AUTOSAR XML (schema 00050)
package /FCADT/ComponentTypes
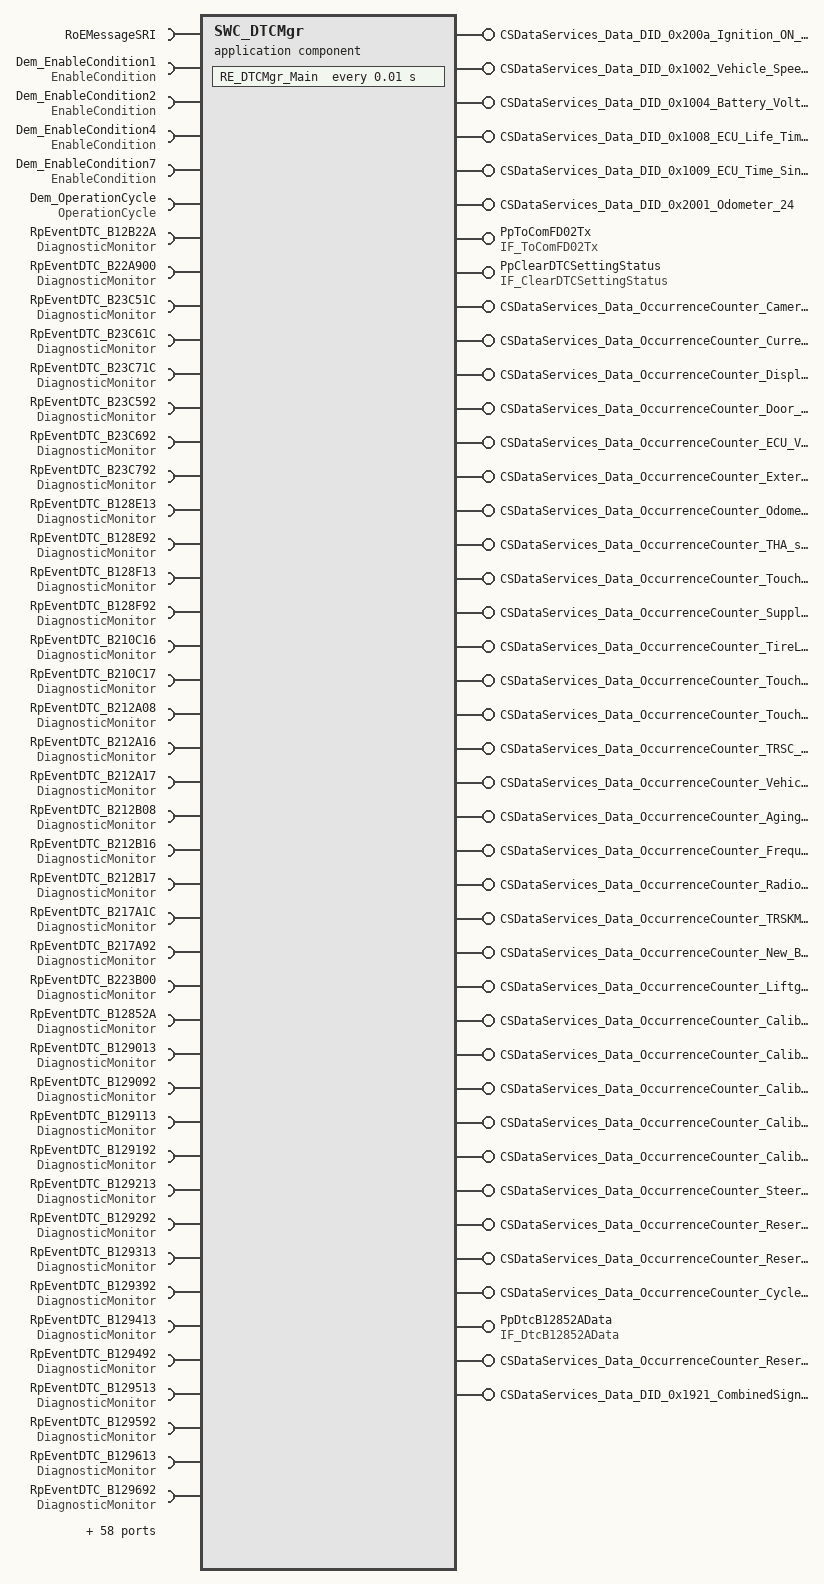
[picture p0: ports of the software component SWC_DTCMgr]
  application sw component type SWC_DTCMgr
    require port RoEMessageSRI: nonqueued-receiver-com-spec{data-element=Data, init-value=8 x 0}, required-interface=RoEMessageSRI
    6 x provide port, all with server-com-spec{operation=ReadData, queue-length=1}:
      CSDataServices_Data_DID_0x200a_Ignition_ON_Counter_24: provided-interface=CSDataServices_Data_DID_0x200a_Ignition_ON_Counter_24
      CSDataServices_Data_DID_0x1002_Vehicle_Speed_24: provided-interface=CSDataServices_Data_DID_0x1002_Vehicle_Speed_24
      CSDataServices_Data_DID_0x1004_Battery_Voltage_24: provided-interface=CSDataServices_Data_DID_0x1004_Battery_Voltage_24
      CSDataServices_Data_DID_0x1008_ECU_Life_Time_24: provided-interface=CSDataServices_Data_DID_0x1008_ECU_Life_Time_24
      CSDataServices_Data_DID_0x1009_ECU_Time_Since_Ignition_ON: provided-interface=CSDataServices_Data_DID_0x1009_ECU_Time_Since_Ignition_ON
      CSDataServices_Data_DID_0x2001_Odometer_24: provided-interface=CSDataServices_Data_DID_0x2001_Odometer_24
    84 x require port:
      Dem_EnableCondition1: client-com-spec=SetEnableCondition, required-interface=EnableCondition
      Dem_EnableCondition2: client-com-spec=SetEnableCondition, required-interface=EnableCondition
      Dem_EnableCondition4: client-com-spec=SetEnableCondition, required-interface=EnableCondition
      Dem_EnableCondition7: client-com-spec=SetEnableCondition, required-interface=EnableCondition
      Dem_OperationCycle: required-com-specs=[SetOperationCycleState, GetOperationCycleState], required-interface=OperationCycle
      RpEventDTC_B12B22A: required-interface=DiagnosticMonitor
        required-com-specs:
          SetEventStatus
          GetEventExtendedDataRecordEx
          GetEventFreezeFrameDataEx
          GetFaultDetectionCounter
          GetDTCOfEvent
          GetEventTested
          GetEventFailed
          GetEventStatus
          GetEventUdsStatus
          ResetEventDebounceStatus
          ResetEventStatus
      RpEventDTC_B22A900: required-interface=DiagnosticMonitor
        required-com-specs:
          SetEventStatus
          GetEventExtendedDataRecordEx
          GetEventFreezeFrameDataEx
          GetFaultDetectionCounter
          GetDTCOfEvent
          GetEventTested
          GetEventFailed
          GetEventStatus
          GetEventUdsStatus
          ResetEventDebounceStatus
          ResetEventStatus
      RpEventDTC_B23C51C: required-interface=DiagnosticMonitor
        required-com-specs:
          SetEventStatus
          GetEventExtendedDataRecordEx
          GetEventFreezeFrameDataEx
          GetFaultDetectionCounter
          GetDTCOfEvent
          GetEventTested
          GetEventFailed
          GetEventStatus
          GetEventUdsStatus
          ResetEventDebounceStatus
          ResetEventStatus
      RpEventDTC_B23C61C: required-interface=DiagnosticMonitor
        required-com-specs:
          SetEventStatus
          GetEventExtendedDataRecordEx
          GetEventFreezeFrameDataEx
          GetFaultDetectionCounter
          GetDTCOfEvent
          GetEventTested
          GetEventFailed
          GetEventStatus
          GetEventUdsStatus
          ResetEventDebounceStatus
          ResetEventStatus
      RpEventDTC_B23C71C: required-interface=DiagnosticMonitor
        required-com-specs:
          SetEventStatus
          GetEventExtendedDataRecordEx
          GetEventFreezeFrameDataEx
          GetFaultDetectionCounter
          GetDTCOfEvent
          GetEventTested
          GetEventFailed
          GetEventStatus
          GetEventUdsStatus
          ResetEventDebounceStatus
          ResetEventStatus
      RpEventDTC_B23C592: required-interface=DiagnosticMonitor
        required-com-specs:
          SetEventStatus
          GetEventExtendedDataRecordEx
          GetEventFreezeFrameDataEx
          GetFaultDetectionCounter
          GetDTCOfEvent
          GetEventTested
          GetEventFailed
          GetEventStatus
          GetEventUdsStatus
          ResetEventDebounceStatus
          ResetEventStatus
      RpEventDTC_B23C692: required-interface=DiagnosticMonitor
        required-com-specs:
          SetEventStatus
          GetEventExtendedDataRecordEx
          GetEventFreezeFrameDataEx
          GetFaultDetectionCounter
          GetDTCOfEvent
          GetEventTested
          GetEventFailed
          GetEventStatus
          GetEventUdsStatus
          ResetEventDebounceStatus
          ResetEventStatus
      RpEventDTC_B23C792: required-interface=DiagnosticMonitor
        required-com-specs:
          SetEventStatus
          GetEventExtendedDataRecordEx
          GetEventFreezeFrameDataEx
          GetFaultDetectionCounter
          GetDTCOfEvent
          GetEventTested
          GetEventFailed
          GetEventStatus
          GetEventUdsStatus
          ResetEventDebounceStatus
          ResetEventStatus
      RpEventDTC_B128E13: required-interface=DiagnosticMonitor
        required-com-specs:
          SetEventStatus
          GetEventExtendedDataRecordEx
          GetEventFreezeFrameDataEx
          GetFaultDetectionCounter
          GetDTCOfEvent
          GetEventTested
          GetEventFailed
          GetEventStatus
          GetEventUdsStatus
          ResetEventDebounceStatus
          ResetEventStatus
      RpEventDTC_B128E92: required-interface=DiagnosticMonitor
        required-com-specs:
          SetEventStatus
          GetEventExtendedDataRecordEx
          GetEventFreezeFrameDataEx
          GetFaultDetectionCounter
          GetDTCOfEvent
          GetEventTested
          GetEventFailed
          GetEventStatus
          GetEventUdsStatus
          ResetEventDebounceStatus
          ResetEventStatus
      RpEventDTC_B128F13: required-interface=DiagnosticMonitor
        required-com-specs:
          SetEventStatus
          GetEventExtendedDataRecordEx
          GetEventFreezeFrameDataEx
          GetFaultDetectionCounter
          GetDTCOfEvent
          GetEventTested
          GetEventFailed
          GetEventStatus
          GetEventUdsStatus
          ResetEventDebounceStatus
          ResetEventStatus
      RpEventDTC_B128F92: required-interface=DiagnosticMonitor
        required-com-specs:
          SetEventStatus
          GetEventExtendedDataRecordEx
          GetEventFreezeFrameDataEx
          GetFaultDetectionCounter
          GetDTCOfEvent
          GetEventTested
          GetEventFailed
          GetEventStatus
          GetEventUdsStatus
          ResetEventDebounceStatus
          ResetEventStatus
      RpEventDTC_B210C16: required-interface=DiagnosticMonitor
        required-com-specs:
          SetEventStatus
          GetEventExtendedDataRecordEx
          GetEventFreezeFrameDataEx
          GetFaultDetectionCounter
          GetDTCOfEvent
          GetEventTested
          GetEventFailed
          GetEventStatus
          GetEventUdsStatus
          ResetEventDebounceStatus
          ResetEventStatus
      RpEventDTC_B210C17: required-interface=DiagnosticMonitor
        required-com-specs:
          SetEventStatus
          GetEventExtendedDataRecordEx
          GetEventFreezeFrameDataEx
          GetFaultDetectionCounter
          GetDTCOfEvent
          GetEventTested
          GetEventFailed
          GetEventStatus
          GetEventUdsStatus
          ResetEventDebounceStatus
          ResetEventStatus
      RpEventDTC_B212A08: required-interface=DiagnosticMonitor
        required-com-specs:
          SetEventStatus
          GetEventExtendedDataRecordEx
          GetEventFreezeFrameDataEx
          GetFaultDetectionCounter
          GetDTCOfEvent
          GetEventTested
          GetEventFailed
          GetEventStatus
          GetEventUdsStatus
          ResetEventDebounceStatus
          ResetEventStatus
      RpEventDTC_B212A16: required-interface=DiagnosticMonitor
        required-com-specs:
          SetEventStatus
          GetEventExtendedDataRecordEx
          GetEventFreezeFrameDataEx
          GetFaultDetectionCounter
          GetDTCOfEvent
          GetEventTested
          GetEventFailed
          GetEventStatus
          GetEventUdsStatus
          ResetEventDebounceStatus
          ResetEventStatus
      RpEventDTC_B212A17: required-interface=DiagnosticMonitor
        required-com-specs:
          SetEventStatus
          GetEventExtendedDataRecordEx
          GetEventFreezeFrameDataEx
          GetFaultDetectionCounter
          GetDTCOfEvent
          GetEventTested
          GetEventFailed
          GetEventStatus
          GetEventUdsStatus
          ResetEventDebounceStatus
          ResetEventStatus
      RpEventDTC_B212B08: required-interface=DiagnosticMonitor
        required-com-specs:
          SetEventStatus
          GetEventExtendedDataRecordEx
          GetEventFreezeFrameDataEx
          GetFaultDetectionCounter
          GetDTCOfEvent
          GetEventTested
          GetEventFailed
          GetEventStatus
          GetEventUdsStatus
          ResetEventDebounceStatus
          ResetEventStatus
      RpEventDTC_B212B16: required-interface=DiagnosticMonitor
        required-com-specs:
          SetEventStatus
          GetEventExtendedDataRecordEx
          GetEventFreezeFrameDataEx
          GetFaultDetectionCounter
          GetDTCOfEvent
          GetEventTested
          GetEventFailed
          GetEventStatus
          GetEventUdsStatus
          ResetEventDebounceStatus
          ResetEventStatus
      RpEventDTC_B212B17: required-interface=DiagnosticMonitor
        required-com-specs:
          SetEventStatus
          GetEventExtendedDataRecordEx
          GetEventFreezeFrameDataEx
          GetFaultDetectionCounter
          GetDTCOfEvent
          GetEventTested
          GetEventFailed
          GetEventStatus
          GetEventUdsStatus
          ResetEventDebounceStatus
          ResetEventStatus
      RpEventDTC_B217A1C: required-interface=DiagnosticMonitor
        required-com-specs:
          SetEventStatus
          GetEventExtendedDataRecordEx
          GetEventFreezeFrameDataEx
          GetFaultDetectionCounter
          GetDTCOfEvent
          GetEventTested
          GetEventFailed
          GetEventStatus
          GetEventUdsStatus
          ResetEventDebounceStatus
          ResetEventStatus
      RpEventDTC_B217A92: required-interface=DiagnosticMonitor
        required-com-specs:
          SetEventStatus
          GetEventExtendedDataRecordEx
          GetEventFreezeFrameDataEx
          GetFaultDetectionCounter
          GetDTCOfEvent
          GetEventTested
          GetEventFailed
          GetEventStatus
          GetEventUdsStatus
          ResetEventDebounceStatus
          ResetEventStatus
      RpEventDTC_B223B00: required-interface=DiagnosticMonitor
        required-com-specs:
          SetEventStatus
          GetEventExtendedDataRecordEx
          GetEventFreezeFrameDataEx
          GetFaultDetectionCounter
          GetDTCOfEvent
          GetEventTested
          GetEventFailed
          GetEventStatus
          GetEventUdsStatus
          ResetEventDebounceStatus
          ResetEventStatus
      RpEventDTC_B12852A: required-interface=DiagnosticMonitor
        required-com-specs:
          SetEventStatus
          GetEventExtendedDataRecordEx
          GetEventFreezeFrameDataEx
          GetFaultDetectionCounter
          GetDTCOfEvent
          GetEventTested
          GetEventFailed
          GetEventStatus
          GetEventUdsStatus
          ResetEventDebounceStatus
          ResetEventStatus
      RpEventDTC_B129013: required-interface=DiagnosticMonitor
        required-com-specs:
          SetEventStatus
          GetEventExtendedDataRecordEx
          GetEventFreezeFrameDataEx
          GetFaultDetectionCounter
          GetDTCOfEvent
          GetEventTested
          GetEventFailed
          GetEventStatus
          GetEventUdsStatus
          ResetEventDebounceStatus
          ResetEventStatus
      RpEventDTC_B129092: required-interface=DiagnosticMonitor
        required-com-specs:
          SetEventStatus
          GetEventExtendedDataRecordEx
          GetEventFreezeFrameDataEx
          GetFaultDetectionCounter
          GetDTCOfEvent
          GetEventTested
          GetEventFailed
          GetEventStatus
          GetEventUdsStatus
          ResetEventDebounceStatus
          ResetEventStatus
      RpEventDTC_B129113: required-interface=DiagnosticMonitor
        required-com-specs:
          SetEventStatus
          GetEventExtendedDataRecordEx
          GetEventFreezeFrameDataEx
          GetFaultDetectionCounter
          GetDTCOfEvent
          GetEventTested
          GetEventFailed
          GetEventStatus
          GetEventUdsStatus
          ResetEventDebounceStatus
          ResetEventStatus
      RpEventDTC_B129192: required-interface=DiagnosticMonitor
        required-com-specs:
          SetEventStatus
          GetEventExtendedDataRecordEx
          GetEventFreezeFrameDataEx
          GetFaultDetectionCounter
          GetDTCOfEvent
          GetEventTested
          GetEventFailed
          GetEventStatus
          GetEventUdsStatus
          ResetEventDebounceStatus
          ResetEventStatus
      RpEventDTC_B129213: required-interface=DiagnosticMonitor
        required-com-specs:
          SetEventStatus
          GetEventExtendedDataRecordEx
          GetEventFreezeFrameDataEx
          GetFaultDetectionCounter
          GetDTCOfEvent
          GetEventTested
          GetEventFailed
          GetEventStatus
          GetEventUdsStatus
          ResetEventDebounceStatus
          ResetEventStatus
      RpEventDTC_B129292: required-interface=DiagnosticMonitor
        required-com-specs:
          SetEventStatus
          GetEventExtendedDataRecordEx
          GetEventFreezeFrameDataEx
          GetFaultDetectionCounter
          GetDTCOfEvent
          GetEventTested
          GetEventFailed
          GetEventStatus
          GetEventUdsStatus
          ResetEventDebounceStatus
          ResetEventStatus
      RpEventDTC_B129313: required-interface=DiagnosticMonitor
        required-com-specs:
          SetEventStatus
          GetEventExtendedDataRecordEx
          GetEventFreezeFrameDataEx
          GetFaultDetectionCounter
          GetDTCOfEvent
          GetEventTested
          GetEventFailed
          GetEventStatus
          GetEventUdsStatus
          ResetEventDebounceStatus
          ResetEventStatus
      RpEventDTC_B129392: required-interface=DiagnosticMonitor
        required-com-specs:
          SetEventStatus
          GetEventExtendedDataRecordEx
          GetEventFreezeFrameDataEx
          GetFaultDetectionCounter
          GetDTCOfEvent
          GetEventTested
          GetEventFailed
          GetEventStatus
          GetEventUdsStatus
          ResetEventDebounceStatus
          ResetEventStatus
      RpEventDTC_B129413: required-interface=DiagnosticMonitor
        required-com-specs:
          SetEventStatus
          GetEventExtendedDataRecordEx
          GetEventFreezeFrameDataEx
          GetFaultDetectionCounter
          GetDTCOfEvent
          GetEventTested
          GetEventFailed
          GetEventStatus
          GetEventUdsStatus
          ResetEventDebounceStatus
          ResetEventStatus
      RpEventDTC_B129492: required-interface=DiagnosticMonitor
        required-com-specs:
          SetEventStatus
          GetEventExtendedDataRecordEx
          GetEventFreezeFrameDataEx
          GetFaultDetectionCounter
          GetDTCOfEvent
          GetEventTested
          GetEventFailed
          GetEventStatus
          GetEventUdsStatus
          ResetEventDebounceStatus
          ResetEventStatus
      RpEventDTC_B129513: required-interface=DiagnosticMonitor
        required-com-specs:
          SetEventStatus
          GetEventExtendedDataRecordEx
          GetEventFreezeFrameDataEx
          GetFaultDetectionCounter
          GetDTCOfEvent
          GetEventTested
          GetEventFailed
          GetEventStatus
          GetEventUdsStatus
          ResetEventDebounceStatus
          ResetEventStatus
      RpEventDTC_B129592: required-interface=DiagnosticMonitor
        required-com-specs:
          SetEventStatus
          GetEventExtendedDataRecordEx
          GetEventFreezeFrameDataEx
          GetFaultDetectionCounter
          GetDTCOfEvent
          GetEventTested
          GetEventFailed
          GetEventStatus
          GetEventUdsStatus
          ResetEventDebounceStatus
          ResetEventStatus
      RpEventDTC_B129613: required-interface=DiagnosticMonitor
        required-com-specs:
          SetEventStatus
          GetEventExtendedDataRecordEx
          GetEventFreezeFrameDataEx
          GetFaultDetectionCounter
          GetDTCOfEvent
          GetEventTested
          GetEventFailed
          GetEventStatus
          GetEventUdsStatus
          ResetEventDebounceStatus
          ResetEventStatus
      RpEventDTC_B129692: required-interface=DiagnosticMonitor
        required-com-specs:
          SetEventStatus
          GetEventExtendedDataRecordEx
          GetEventFreezeFrameDataEx
          GetFaultDetectionCounter
          GetDTCOfEvent
          GetEventTested
          GetEventFailed
          GetEventStatus
          GetEventUdsStatus
          ResetEventDebounceStatus
          ResetEventStatus
      RpEventDTC_B129713: required-interface=DiagnosticMonitor
        required-com-specs:
          SetEventStatus
          GetEventExtendedDataRecordEx
          GetEventFreezeFrameDataEx
          GetFaultDetectionCounter
          GetDTCOfEvent
          GetEventTested
          GetEventFailed
          GetEventStatus
          GetEventUdsStatus
          ResetEventDebounceStatus
          ResetEventStatus
      RpEventDTC_B129792: required-interface=DiagnosticMonitor
        required-com-specs:
          SetEventStatus
          GetEventExtendedDataRecordEx
          GetEventFreezeFrameDataEx
          GetFaultDetectionCounter
          GetDTCOfEvent
          GetEventTested
          GetEventFailed
          GetEventStatus
          GetEventUdsStatus
          ResetEventDebounceStatus
          ResetEventStatus
      RpEventDTC_B129813: required-interface=DiagnosticMonitor
        required-com-specs:
          SetEventStatus
          GetEventExtendedDataRecordEx
          GetEventFreezeFrameDataEx
          GetFaultDetectionCounter
          GetDTCOfEvent
          GetEventTested
          GetEventFailed
          GetEventStatus
          GetEventUdsStatus
          ResetEventDebounceStatus
          ResetEventStatus
      RpEventDTC_B129892: required-interface=DiagnosticMonitor
        required-com-specs:
          SetEventStatus
          GetEventExtendedDataRecordEx
          GetEventFreezeFrameDataEx
          GetFaultDetectionCounter
          GetDTCOfEvent
          GetEventTested
          GetEventFailed
          GetEventStatus
          GetEventUdsStatus
          ResetEventDebounceStatus
          ResetEventStatus
      RpEventDTC_B129913: required-interface=DiagnosticMonitor
        required-com-specs:
          SetEventStatus
          GetEventExtendedDataRecordEx
          GetEventFreezeFrameDataEx
          GetFaultDetectionCounter
          GetDTCOfEvent
          GetEventTested
          GetEventFailed
          GetEventStatus
          GetEventUdsStatus
          ResetEventDebounceStatus
          ResetEventStatus
      RpEventDTC_B129992: required-interface=DiagnosticMonitor
        required-com-specs:
          SetEventStatus
          GetEventExtendedDataRecordEx
          GetEventFreezeFrameDataEx
          GetFaultDetectionCounter
          GetDTCOfEvent
          GetEventTested
          GetEventFailed
          GetEventStatus
          GetEventUdsStatus
          ResetEventDebounceStatus
          ResetEventStatus
      RpEventDTC_B228600: required-interface=DiagnosticMonitor
        required-com-specs:
          SetEventStatus
          GetEventExtendedDataRecordEx
          GetEventFreezeFrameDataEx
          GetFaultDetectionCounter
          GetDTCOfEvent
          GetEventTested
          GetEventFailed
          GetEventStatus
          GetEventUdsStatus
          ResetEventDebounceStatus
          ResetEventStatus
      RpEventDTC_C221200: required-interface=DiagnosticMonitor
        required-com-specs:
          SetEventStatus
          GetEventExtendedDataRecordEx
          GetEventFreezeFrameDataEx
          GetFaultDetectionCounter
          GetDTCOfEvent
          GetEventTested
          GetEventFailed
          GetEventStatus
          GetEventUdsStatus
          ResetEventDebounceStatus
          ResetEventStatus
      RpEventDTC_U12B900: required-interface=DiagnosticMonitor
        required-com-specs:
          SetEventStatus
          GetEventExtendedDataRecordEx
          GetEventFreezeFrameDataEx
          GetFaultDetectionCounter
          GetDTCOfEvent
          GetEventTested
          GetEventFailed
          GetEventStatus
          GetEventUdsStatus
          ResetEventDebounceStatus
          ResetEventStatus
      RpEventDTC_U14A000: required-interface=DiagnosticMonitor
        required-com-specs:
          SetEventStatus
          GetEventExtendedDataRecordEx
          GetEventFreezeFrameDataEx
          GetFaultDetectionCounter
          GetDTCOfEvent
          GetEventTested
          GetEventFailed
          GetEventStatus
          GetEventUdsStatus
          ResetEventDebounceStatus
          ResetEventStatus
      RpEventDTC_U100B00: required-interface=DiagnosticMonitor
        required-com-specs:
          SetEventStatus
          GetEventExtendedDataRecordEx
          GetEventFreezeFrameDataEx
          GetFaultDetectionCounter
          GetDTCOfEvent
          GetEventTested
          GetEventFailed
          GetEventStatus
          GetEventUdsStatus
          ResetEventDebounceStatus
          ResetEventStatus
      RpEventDTC_U104E00: required-interface=DiagnosticMonitor
        required-com-specs:
          SetEventStatus
          GetEventExtendedDataRecordEx
          GetEventFreezeFrameDataEx
          GetFaultDetectionCounter
          GetDTCOfEvent
          GetEventTested
          GetEventFailed
          GetEventStatus
          GetEventUdsStatus
          ResetEventDebounceStatus
          ResetEventStatus
      RpEventDTC_U010000: required-interface=DiagnosticMonitor
        required-com-specs:
          SetEventStatus
          GetEventExtendedDataRecordEx
          GetEventFreezeFrameDataEx
          GetFaultDetectionCounter
          GetDTCOfEvent
          GetEventTested
          GetEventFailed
          GetEventStatus
          GetEventUdsStatus
          ResetEventDebounceStatus
          ResetEventStatus
      RpEventDTC_U012900: required-interface=DiagnosticMonitor
        required-com-specs:
          SetEventStatus
          GetEventExtendedDataRecordEx
          GetEventFreezeFrameDataEx
          GetFaultDetectionCounter
          GetDTCOfEvent
          GetEventTested
          GetEventFailed
          GetEventStatus
          GetEventUdsStatus
          ResetEventDebounceStatus
          ResetEventStatus
      RpEventDTC_U013100: required-interface=DiagnosticMonitor
        required-com-specs:
          SetEventStatus
          GetEventExtendedDataRecordEx
          GetEventFreezeFrameDataEx
          GetFaultDetectionCounter
          GetDTCOfEvent
          GetEventTested
          GetEventFailed
          GetEventStatus
          GetEventUdsStatus
          ResetEventDebounceStatus
          ResetEventStatus
      RpEventDTC_U014000: required-interface=DiagnosticMonitor
        required-com-specs:
          SetEventStatus
          GetEventExtendedDataRecordEx
          GetEventFreezeFrameDataEx
          GetFaultDetectionCounter
          GetDTCOfEvent
          GetEventTested
          GetEventFailed
          GetEventStatus
          GetEventUdsStatus
          ResetEventDebounceStatus
          ResetEventStatus
      RpEventDTC_U015100: required-interface=DiagnosticMonitor
        required-com-specs:
          SetEventStatus
          GetEventExtendedDataRecordEx
          GetEventFreezeFrameDataEx
          GetFaultDetectionCounter
          GetDTCOfEvent
          GetEventTested
          GetEventFailed
          GetEventStatus
          GetEventUdsStatus
          ResetEventDebounceStatus
          ResetEventStatus
      RpEventDTC_U018400: required-interface=DiagnosticMonitor
        required-com-specs:
          SetEventStatus
          GetEventExtendedDataRecordEx
          GetEventFreezeFrameDataEx
          GetFaultDetectionCounter
          GetDTCOfEvent
          GetEventTested
          GetEventFailed
          GetEventStatus
          GetEventUdsStatus
          ResetEventDebounceStatus
          ResetEventStatus
      RpEventDTC_U026400: required-interface=DiagnosticMonitor
        required-com-specs:
          SetEventStatus
          GetEventExtendedDataRecordEx
          GetEventFreezeFrameDataEx
          GetFaultDetectionCounter
          GetDTCOfEvent
          GetEventTested
          GetEventFailed
          GetEventStatus
          GetEventUdsStatus
          ResetEventDebounceStatus
          ResetEventStatus
      RpEventDTC_U026500: required-interface=DiagnosticMonitor
        required-com-specs:
          SetEventStatus
          GetEventExtendedDataRecordEx
          GetEventFreezeFrameDataEx
          GetFaultDetectionCounter
          GetDTCOfEvent
          GetEventTested
          GetEventFailed
          GetEventStatus
          GetEventUdsStatus
          ResetEventDebounceStatus
          ResetEventStatus
      RpEventDTC_U026600: required-interface=DiagnosticMonitor
        required-com-specs:
          SetEventStatus
          GetEventExtendedDataRecordEx
          GetEventFreezeFrameDataEx
          GetFaultDetectionCounter
          GetDTCOfEvent
          GetEventTested
          GetEventFailed
          GetEventStatus
          GetEventUdsStatus
          ResetEventDebounceStatus
          ResetEventStatus
      RpEventDTC_U026700: required-interface=DiagnosticMonitor
        required-com-specs:
          SetEventStatus
          GetEventExtendedDataRecordEx
          GetEventFreezeFrameDataEx
          GetFaultDetectionCounter
          GetDTCOfEvent
          GetEventTested
          GetEventFailed
          GetEventStatus
          GetEventUdsStatus
          ResetEventDebounceStatus
          ResetEventStatus
      RpEventDTC_U040100: required-interface=DiagnosticMonitor
        required-com-specs:
          SetEventStatus
          GetEventExtendedDataRecordEx
          GetEventFreezeFrameDataEx
          GetFaultDetectionCounter
          GetDTCOfEvent
          GetEventTested
          GetEventFailed
          GetEventStatus
          GetEventUdsStatus
          ResetEventDebounceStatus
          ResetEventStatus
      RpEventDTC_U041800: required-interface=DiagnosticMonitor
        required-com-specs:
          SetEventStatus
          GetEventExtendedDataRecordEx
          GetEventFreezeFrameDataEx
          GetFaultDetectionCounter
          GetDTCOfEvent
          GetEventTested
          GetEventFailed
          GetEventStatus
          GetEventUdsStatus
          ResetEventDebounceStatus
          ResetEventStatus
      RpEventDTC_U042000: required-interface=DiagnosticMonitor
        required-com-specs:
          SetEventStatus
          GetEventExtendedDataRecordEx
          GetEventFreezeFrameDataEx
          GetFaultDetectionCounter
          GetDTCOfEvent
          GetEventTested
          GetEventFailed
          GetEventStatus
          GetEventUdsStatus
          ResetEventDebounceStatus
          ResetEventStatus
      RpEventDTC_U042200: required-interface=DiagnosticMonitor
        required-com-specs:
          SetEventStatus
          GetEventExtendedDataRecordEx
          GetEventFreezeFrameDataEx
          GetFaultDetectionCounter
          GetDTCOfEvent
          GetEventTested
          GetEventFailed
          GetEventStatus
          GetEventUdsStatus
          ResetEventDebounceStatus
          ResetEventStatus
      RpEventDTC_U045500: required-interface=DiagnosticMonitor
        required-com-specs:
          SetEventStatus
          GetEventExtendedDataRecordEx
          GetEventFreezeFrameDataEx
          GetFaultDetectionCounter
          GetDTCOfEvent
          GetEventTested
          GetEventFailed
          GetEventStatus
          GetEventUdsStatus
          ResetEventDebounceStatus
          ResetEventStatus
      RpEventDTC_U048500: required-interface=DiagnosticMonitor
        required-com-specs:
          SetEventStatus
          GetEventExtendedDataRecordEx
          GetEventFreezeFrameDataEx
          GetFaultDetectionCounter
          GetDTCOfEvent
          GetEventTested
          GetEventFailed
          GetEventStatus
          GetEventUdsStatus
          ResetEventDebounceStatus
          ResetEventStatus
      RpECUTimeSinceIGON: nonqueued-receiver-com-spec{data-element=ECUTimeStamp_IGON, init-value=0}, required-interface=IF_ECUTimeSince_IGON
      RpECUTimeStamp: nonqueued-receiver-com-spec{data-element=ECUTimeStamp, init-value=0}, required-interface=IF_ECUTimeStamp
      RpIgOnCounter: nonqueued-receiver-com-spec{data-element=IGCounter, init-value=0}, required-interface=IF_IGON_Counter
      Dem_EnableCondition5: client-com-spec=SetEnableCondition, required-interface=EnableCondition
      RpReadVoltInfo: client-com-spec=GetVoltageInfo, required-interface=IF_ReadVoltInfo
      RpSystemStateManager: nonqueued-receiver-com-spec{data-element=SysM_State, filter=data-filter-type=ALWAYS, init-value=0}, required-interface=IF_SystemStateManager
      RpProxiToSWC: required-interface=IF_ProxiToSWC
        required-com-specs:
          data-element=TyreSz_u16, filter=data-filter-type=ALWAYS
          data-element=SurroundViewCam_u8, filter=data-filter-type=ALWAYS
          data-element=Fullautomaticparking, filter=data-filter-type=ALWAYS
          data-element=Pamtuningset, filter=data-filter-type=ALWAYS
          data-element=PRX_CanNod27_b, filter=data-filter-type=ALWAYS
          data-element=Parkwithstop_u8, filter=data-filter-type=ALWAYS
          data-element=Trailerhitchassist_u8, filter=data-filter-type=ALWAYS
          data-element=PAMConfig_u8, filter=data-filter-type=ALWAYS
      Dem_EnableCondition1_4_8: client-com-spec=SetEnableCondition, required-interface=EnableCondition
      Dem_EnableCondition1_8: client-com-spec=SetEnableCondition, required-interface=EnableCondition
      RpToSwcFD02Rx: required-interface=IF_FromComFD02Rx
        required-com-specs:
          data-element=Altitude_RMSE_C2, filter=data-filter-type=ALWAYS, init-value=255
          data-element=Battery_Volt_1, filter=data-filter-type=ALWAYS, init-value=0
          data-element=BSM_THA_Brk_Resp, filter=data-filter-type=ALWAYS, init-value=0
          data-element=CurrentCanNMState_FD01_BCM, filter=data-filter-type=ALWAYS, init-value=0
          data-element=CurrentCanNMState_FD01_SGW, filter=data-filter-type=ALWAYS, init-value=0
          data-element=CurrentCanNMState_FD02_BCM, filter=data-filter-type=ALWAYS, init-value=0
          data-element=CurrentCanNMState_FD02_BSM2, filter=data-filter-type=ALWAYS, init-value=0
          data-element=CurrentCanNMState_FD02_CADM2, filter=data-filter-type=ALWAYS, init-value=0
          data-element=CurrentCanNMState_FD02_EPS, filter=data-filter-type=ALWAYS, init-value=0
          data-element=CurrentCanNMState_FD02_ORC, filter=data-filter-type=ALWAYS, init-value=0
          data-element=CurrentCanNMState_FD02_SGW, filter=data-filter-type=ALWAYS, init-value=0
          data-element=CurrentCanNMState_FD02_TRLR_REV, filter=data-filter-type=ALWAYS, init-value=0
          data-element=CurrentCanNMState_FD03_BCM, filter=data-filter-type=ALWAYS, init-value=0
          data-element=CurrentCanNMState_FD03_SGW, filter=data-filter-type=ALWAYS, init-value=0
          data-element=CurrentCanNMState_FD04_BCM, filter=data-filter-type=ALWAYS, init-value=0
          data-element=CurrentCanNMState_FD08_SGW, filter=data-filter-type=ALWAYS, init-value=0
          data-element=CurrentCanNMState_FD11_SGW, filter=data-filter-type=ALWAYS, init-value=0
          data-element=CurrentFailSts_FD01_BCM, filter=data-filter-type=ALWAYS, init-value=0
          data-element=CurrentFailSts_FD01_SGW, filter=data-filter-type=ALWAYS, init-value=0
          data-element=CurrentFailSts_FD02_BCM, filter=data-filter-type=ALWAYS, init-value=0
          data-element=CurrentFailSts_FD02_BSM2, filter=data-filter-type=ALWAYS, init-value=0
          data-element=CurrentFailSts_FD02_CADM2, filter=data-filter-type=ALWAYS, init-value=0
          data-element=CurrentFailSts_FD02_EPS, filter=data-filter-type=ALWAYS, init-value=0
          data-element=CurrentFailSts_FD02_ORC, filter=data-filter-type=ALWAYS, init-value=0
          data-element=CurrentFailSts_FD02_SGW, filter=data-filter-type=ALWAYS, init-value=0
          data-element=CurrentFailSts_FD02_TRLR_REV, filter=data-filter-type=ALWAYS, init-value=0
          data-element=CurrentFailSts_FD03_BCM, filter=data-filter-type=ALWAYS, init-value=0
          data-element=CurrentFailSts_FD03_SGW, filter=data-filter-type=ALWAYS, init-value=0
          data-element=CurrentFailSts_FD04_BCM, filter=data-filter-type=ALWAYS, init-value=0
          data-element=CurrentFailSts_FD08_SGW, filter=data-filter-type=ALWAYS, init-value=0
          data-element=CurrentFailSts_FD11_SGW, filter=data-filter-type=ALWAYS, init-value=0
          data-element=DeltaTimestamp_IMUdata, filter=data-filter-type=ALWAYS, init-value=255
          data-element=DES_FD01_BCM, filter=data-filter-type=ALWAYS, init-value=0
          data-element=DES_FD01_SGW, filter=data-filter-type=ALWAYS, init-value=0
          data-element=DES_FD02_BCM, filter=data-filter-type=ALWAYS, init-value=0
          data-element=DES_FD02_BSM2, filter=data-filter-type=ALWAYS, init-value=0
          data-element=DES_FD02_CADM2, filter=data-filter-type=ALWAYS, init-value=0
          data-element=DES_FD02_EPS, filter=data-filter-type=ALWAYS, init-value=0
          data-element=DES_FD02_ORC, filter=data-filter-type=ALWAYS, init-value=0
          data-element=DES_FD02_SGW, filter=data-filter-type=ALWAYS, init-value=0
          data-element=DES_FD02_TRLR_REV, filter=data-filter-type=ALWAYS, init-value=0
          data-element=DES_FD03_BCM, filter=data-filter-type=ALWAYS, init-value=0
          data-element=DES_FD03_SGW, filter=data-filter-type=ALWAYS, init-value=0
          data-element=DES_FD04_BCM, filter=data-filter-type=ALWAYS, init-value=0
          data-element=DES_FD08_SGW, filter=data-filter-type=ALWAYS, init-value=0
          data-element=DES_FD11_SGW, filter=data-filter-type=ALWAYS, init-value=0
          data-element=Digit_{01..11}, filter=data-filter-type=ALWAYS, init-value=0
          data-element=EOL_FD01_BCM, filter=data-filter-type=ALWAYS, init-value=0
          data-element=EOL_FD01_SGW, filter=data-filter-type=ALWAYS, init-value=0
          data-element=EOL_FD02_BCM, filter=data-filter-type=ALWAYS, init-value=0
          data-element=EOL_FD02_BSM2, filter=data-filter-type=ALWAYS, init-value=0
          data-element=EOL_FD02_CADM2, filter=data-filter-type=ALWAYS, init-value=0
          data-element=EOL_FD02_EPS, filter=data-filter-type=ALWAYS, init-value=0
          data-element=EOL_FD02_ORC, filter=data-filter-type=ALWAYS, init-value=0
          data-element=EOL_FD02_SGW, filter=data-filter-type=ALWAYS, init-value=0
          data-element=EOL_FD02_TRLR_REV, filter=data-filter-type=ALWAYS, init-value=0
          data-element=EOL_FD03_BCM, filter=data-filter-type=ALWAYS, init-value=0
          data-element=EOL_FD03_SGW, filter=data-filter-type=ALWAYS, init-value=0
          data-element=EOL_FD04_BCM, filter=data-filter-type=ALWAYS, init-value=0
          data-element=EOL_FD08_SGW, filter=data-filter-type=ALWAYS, init-value=0
          data-element=EOL_FD11_SGW, filter=data-filter-type=ALWAYS, init-value=0
          data-element=EPBSts, filter=data-filter-type=ALWAYS, init-value=0
          data-element=GenericFailSts_FD01_BCM, filter=data-filter-type=ALWAYS, init-value=0
          data-element=GenericFailSts_FD01_SGW, filter=data-filter-type=ALWAYS, init-value=0
          data-element=GenericFailSts_FD02_BCM, filter=data-filter-type=ALWAYS, init-value=0
          data-element=GenericFailSts_FD02_BSM2, filter=data-filter-type=ALWAYS, init-value=0
          data-element=GenericFailSts_FD02_CADM2, filter=data-filter-type=ALWAYS, init-value=0
          data-element=GenericFailSts_FD02_EPS, filter=data-filter-type=ALWAYS, init-value=0
          data-element=GenericFailSts_FD02_ORC, filter=data-filter-type=ALWAYS, init-value=0
          data-element=GenericFailSts_FD02_SGW, filter=data-filter-type=ALWAYS, init-value=0
          data-element=GenericFailSts_FD02_TRLR_REV, filter=data-filter-type=ALWAYS, init-value=0
          data-element=GenericFailSts_FD03_BCM, filter=data-filter-type=ALWAYS, init-value=0
          data-element=GenericFailSts_FD03_SGW, filter=data-filter-type=ALWAYS, init-value=0
          data-element=GenericFailSts_FD04_BCM, filter=data-filter-type=ALWAYS, init-value=0
          data-element=GenericFailSts_FD08_SGW, filter=data-filter-type=ALWAYS, init-value=0
          data-element=GenericFailSts_FD11_SGW, filter=data-filter-type=ALWAYS, init-value=0
          data-element=Heading_Angle_C2, filter=data-filter-type=ALWAYS, init-value=65535
          data-element=IgnitionOnCounter, filter=data-filter-type=ALWAYS, init-value=0
          data-element=LatAcceleration_C2, filter=data-filter-type=ALWAYS, init-value=4095
          data-element=LatAccelerationOffset_BSM, filter=data-filter-type=ALWAYS, init-value=255
          data-element=Latitude_RMSE_C2, filter=data-filter-type=ALWAYS, init-value=255
          data-element=LHF_FastPulseCounter, filter=data-filter-type=ALWAYS, init-value=0
          data-element=LHF_Spin, filter=data-filter-type=ALWAYS, init-value=0
          data-element=LHFWheelSpeed, filter=data-filter-type=ALWAYS, init-value=0
          data-element=LHR_FastPulseCounter, filter=data-filter-type=ALWAYS, init-value=0
          data-element=LHR_Spin, filter=data-filter-type=ALWAYS, init-value=0
          data-element=LHRWheelSpeed, filter=data-filter-type=ALWAYS, init-value=0
          data-element=LongAcceleration_C2, filter=data-filter-type=ALWAYS, init-value=4095
          data-element=LongAccelerationOffset_BSM, filter=data-filter-type=ALWAYS, init-value=255
          data-element=Longitude_RMSE_C2, filter=data-filter-type=ALWAYS, init-value=255
          data-element=OperationalModeSts, filter=data-filter-type=ALWAYS, init-value=0
          data-element=Pitch_RMSE_C2, filter=data-filter-type=ALWAYS, init-value=255
          data-element=PitchRate_C2, filter=data-filter-type=ALWAYS, init-value=4095
          data-element=PreviousCanNMState_FD01_BCM, filter=data-filter-type=ALWAYS, init-value=0
          data-element=PreviousCanNMState_FD01_SGW, filter=data-filter-type=ALWAYS, init-value=0
          data-element=PreviousCanNMState_FD02_BCM, filter=data-filter-type=ALWAYS, init-value=0
          data-element=PreviousCanNMState_FD02_BSM2, filter=data-filter-type=ALWAYS, init-value=0
          data-element=PreviousCanNMState_FD02_CADM2, filter=data-filter-type=ALWAYS, init-value=0
          data-element=PreviousCanNMState_FD02_EPS, filter=data-filter-type=ALWAYS, init-value=0
          data-element=PreviousCanNMState_FD02_ORC, filter=data-filter-type=ALWAYS, init-value=0
          data-element=PreviousCanNMState_FD02_SGW, filter=data-filter-type=ALWAYS, init-value=0
          data-element=PreviousCanNMState_FD02_TRLR_REV, filter=data-filter-type=ALWAYS, init-value=0
          data-element=PreviousCanNMState_FD03_BCM, filter=data-filter-type=ALWAYS, init-value=0
          data-element=PreviousCanNMState_FD03_SGW, filter=data-filter-type=ALWAYS, init-value=0
          data-element=PreviousCanNMState_FD04_BCM, filter=data-filter-type=ALWAYS, init-value=0
          data-element=PreviousCanNMState_FD08_SGW, filter=data-filter-type=ALWAYS, init-value=0
          data-element=PreviousCanNMState_FD11_SGW, filter=data-filter-type=ALWAYS, init-value=0
          data-element=REF_VEH_SPEED, filter=data-filter-type=ALWAYS, init-value=1023
          data-element=RemStActvSts, filter=data-filter-type=ALWAYS, init-value=0
          data-element=RHF_FastPulseCounter, filter=data-filter-type=ALWAYS, init-value=0
          data-element=RHF_Spin, filter=data-filter-type=ALWAYS, init-value=0
          data-element=RHFWheelSpeed, filter=data-filter-type=ALWAYS, init-value=0
          data-element=RHR_FastPulseCounter, filter=data-filter-type=ALWAYS, init-value=0
          data-element=RHR_Spin, filter=data-filter-type=ALWAYS, init-value=0
          data-element=RHRWheelSpeed, filter=data-filter-type=ALWAYS, init-value=0
          data-element=Roll_RMSE_C2, filter=data-filter-type=ALWAYS, init-value=255
          data-element=RollRate_C2, filter=data-filter-type=ALWAYS, init-value=4095
          data-element=SBR1RowDriverSeatSts, filter=data-filter-type=ALWAYS, init-value=3
          data-element=StayActiveSource_FD01_BCM, filter=data-filter-type=ALWAYS, init-value=0
          data-element=StayActiveSource_FD01_SGW, filter=data-filter-type=ALWAYS, init-value=0
          data-element=StayActiveSource_FD02_BCM, filter=data-filter-type=ALWAYS, init-value=0
          data-element=StayActiveSource_FD02_BSM2, filter=data-filter-type=ALWAYS, init-value=0
          data-element=StayActiveSource_FD02_CADM2, filter=data-filter-type=ALWAYS, init-value=0
          data-element=StayActiveSource_FD02_EPS, filter=data-filter-type=ALWAYS, init-value=0
          data-element=StayActiveSource_FD02_ORC, filter=data-filter-type=ALWAYS, init-value=0
          data-element=StayActiveSource_FD02_SGW, filter=data-filter-type=ALWAYS, init-value=0
          data-element=StayActiveSource_FD02_TRLR_REV, filter=data-filter-type=ALWAYS, init-value=0
          data-element=StayActiveSource_FD03_BCM, filter=data-filter-type=ALWAYS, init-value=0
          data-element=StayActiveSource_FD03_SGW, filter=data-filter-type=ALWAYS, init-value=0
          data-element=StayActiveSource_FD04_BCM, filter=data-filter-type=ALWAYS, init-value=0
          data-element=StayActiveSource_FD08_SGW, filter=data-filter-type=ALWAYS, init-value=0
          data-element=StayActiveSource_FD11_SGW, filter=data-filter-type=ALWAYS, init-value=0
          data-element=TotalOdometer, filter=data-filter-type=ALWAYS, init-value=0
          data-element=TRSC_CenterBtn_Sts, filter=data-filter-type=ALWAYS, init-value=0
          data-element=TRSC_EnableBtn_Sts, filter=data-filter-type=ALWAYS, init-value=0
          data-element=TRSC_RawKnob, filter=data-filter-type=ALWAYS, init-value=0
          data-element=TurnIndicatorSts, filter=data-filter-type=ALWAYS, init-value=0
          data-element=VehicleStandStillSts, filter=data-filter-type=ALWAYS, init-value=1
          data-element=VerticalAcceleration_C2, filter=data-filter-type=ALWAYS, init-value=4095
          data-element=WakeupSource_FD01_ADCM, filter=data-filter-type=ALWAYS, init-value=0
          data-element=WakeupSource_FD01_BCM, filter=data-filter-type=ALWAYS, init-value=0
          data-element=WakeupSource_FD01_SGW, filter=data-filter-type=ALWAYS, init-value=0
          data-element=WakeupSource_FD02_BCM, filter=data-filter-type=ALWAYS, init-value=0
          data-element=WakeupSource_FD02_BSM2, filter=data-filter-type=ALWAYS, init-value=0
          data-element=WakeupSource_FD02_CADM2, filter=data-filter-type=ALWAYS, init-value=0
          data-element=WakeupSource_FD02_EPS, filter=data-filter-type=ALWAYS, init-value=0
          data-element=WakeupSource_FD02_ORC, filter=data-filter-type=ALWAYS, init-value=0
          data-element=WakeupSource_FD02_SGW, filter=data-filter-type=ALWAYS, init-value=0
          data-element=WakeupSource_FD02_TRLR_REV, filter=data-filter-type=ALWAYS, init-value=0
          data-element=WakeupSource_FD03_BCM, filter=data-filter-type=ALWAYS, init-value=0
          data-element=WakeupSource_FD03_SGW, filter=data-filter-type=ALWAYS, init-value=0
          data-element=WakeupSource_FD04_BCM, filter=data-filter-type=ALWAYS, init-value=0
          data-element=WakeupSource_FD08_SGW, filter=data-filter-type=ALWAYS, init-value=0
          data-element=WakeupSource_FD11_SGW, filter=data-filter-type=ALWAYS, init-value=0
          data-element=YawRate_C2, filter=data-filter-type=ALWAYS, init-value=4095
          data-element=YawRate_RMSE_C2, filter=data-filter-type=ALWAYS, init-value=255
      RpToSwcSafeFD02Rx: required-interface=IF_FromComSafeFD02Rx
        required-com-specs:
          data-element=Active_Park_Mode, filter=data-filter-type=ALWAYS, init-value=0
          data-element=Active_Park_Prox_Chime, filter=data-filter-type=ALWAYS, init-value=0
          data-element=APARequestSts, filter=data-filter-type=ALWAYS, init-value=0
          data-element=Backup_Cam_Delay, filter=data-filter-type=ALWAYS, init-value=0
          data-element=Brk_Stat, filter=data-filter-type=ALWAYS, init-value=0
          data-element=CmdIgnSts, filter=data-filter-type=ALWAYS, init-value=0
          data-element=DriverDoorSts, filter=data-filter-type=ALWAYS, init-value=0
          data-element=DynamicGrid, filter=data-filter-type=ALWAYS, init-value=1
          data-element=ExternalTemperature, filter=data-filter-type=ALWAYS, init-value=0
          data-element=FT_PAMRequestSts, filter=data-filter-type=ALWAYS, init-value=0
          data-element=Fwrd_Cam_Guidelines, filter=data-filter-type=ALWAYS, init-value=0
          data-element=GearEngaged, filter=data-filter-type=ALWAYS, init-value=0
          data-element=HAS_Status_C2, filter=data-filter-type=ALWAYS, init-value=0
          data-element=LanguageSelection, filter=data-filter-type=ALWAYS, init-value=0
          data-element=LatAcceleration_BSM, filter=data-filter-type=ALWAYS, init-value=4095
          data-element=LHRDoorSts, filter=data-filter-type=ALWAYS, init-value=0
          data-element=LongAcceleration_BSM, filter=data-filter-type=ALWAYS, init-value=4095
          data-element=LwsAngle, filter=data-filter-type=ALWAYS, init-value=0
          data-element=LwsAngleType, filter=data-filter-type=ALWAYS, init-value=0
          data-element=LwsSpeed, filter=data-filter-type=ALWAYS, init-value=0
          data-element=MRM_STATUS_C2, filter=data-filter-type=ALWAYS, init-value=0
          data-element=PamChimeVolumeFront, filter=data-filter-type=ALWAYS, init-value=1
          data-element=PamChimeVolumeRear, filter=data-filter-type=ALWAYS, init-value=1
          data-element=PAMRequestSts, filter=data-filter-type=ALWAYS, init-value=0
          data-element=PsngrDoorSts, filter=data-filter-type=ALWAYS, init-value=0
          data-element=Rear_Brk_Asst, filter=data-filter-type=ALWAYS, init-value=0
          data-element=RHatchSts, filter=data-filter-type=ALWAYS, init-value=0
          data-element=RHRDoorSts, filter=data-filter-type=ALWAYS, init-value=0
          data-element=ShiftLeverPosition, filter=data-filter-type=ALWAYS, init-value=0
          data-element=SVC_Guidelines, filter=data-filter-type=ALWAYS, init-value=0
          data-element=TargetGear, filter=data-filter-type=ALWAYS, init-value=15
          data-element=TCASERANGESTATUS, filter=data-filter-type=ALWAYS, init-value=0
          data-element=TGW_CAMERA_DISP_STAT, filter=data-filter-type=ALWAYS, init-value=0
          data-element=TrailerConnectionSts, filter=data-filter-type=ALWAYS, init-value=0
          data-element=TRANS_ADAS_Inhibit, filter=data-filter-type=ALWAYS, init-value=0
          data-element=TransmissionSailingSts, filter=data-filter-type=ALWAYS, init-value=0
          data-element=VehicleSpeedVSOSig, filter=data-filter-type=ALWAYS, init-value=0
          data-element=YawRate_BSM, filter=data-filter-type=ALWAYS, init-value=4095
          data-element=VIN_MSG, filter=data-filter-type=ALWAYS
          data-element=VIN_DATA, filter=data-filter-type=ALWAYS
          data-element=RR_Lvl_Adj, filter=data-filter-type=ALWAYS
          data-element=RR_Lvl, filter=data-filter-type=ALWAYS
          data-element=RL_Lvl_Adj, filter=data-filter-type=ALWAYS
          data-element=RL_Lvl, filter=data-filter-type=ALWAYS
          data-element=HU_TRSC_EnableBtn_Sts, filter=data-filter-type=ALWAYS
          data-element=GearEngagedForDisplay, filter=data-filter-type=ALWAYS
          data-element=FR_Lvl_Adj, filter=data-filter-type=ALWAYS
          data-element=FR_Lvl, filter=data-filter-type=ALWAYS
          data-element=FL_Lvl_Adj, filter=data-filter-type=ALWAYS
          data-element=FL_Lvl, filter=data-filter-type=ALWAYS
          data-element=ESS_ENG_ST_W, filter=data-filter-type=ALWAYS
          data-element=EngineSts_W, filter=data-filter-type=ALWAYS
          data-element=ECM_TRSC_Resp, filter=data-filter-type=ALWAYS
          data-element=ECM_THA_Resp, filter=data-filter-type=ALWAYS
          data-element=ASCM_SysFail, filter=data-filter-type=ALWAYS
          data-element=ASCM_Stat, filter=data-filter-type=ALWAYS
          data-element=PdlPosActual, filter=data-filter-type=ALWAYS
          data-element=THA_SteeringTouchStat, filter=data-filter-type=ALWAYS
          data-element=EPS_THA_SteeringTorqueResp, filter=data-filter-type=ALWAYS
          data-element=EPS_THA_DriverTorqueOverride, filter=data-filter-type=ALWAYS
          data-element=EPS_SteeringTouq_Resp, filter=data-filter-type=ALWAYS
          data-element=EPS_SteeringTouchStat, filter=data-filter-type=ALWAYS
          data-element=ShiftLeverPositionReq, filter=data-filter-type=ALWAYS
          data-element=Shifter_ADAS_Inhibit, filter=data-filter-type=ALWAYS
          data-element=ITBM_TrlrStat, filter=data-filter-type=ALWAYS
          data-element=CM_TCH_Y_COORD, filter=data-filter-type=ALWAYS
          data-element=CM_TCH_X_COORD, filter=data-filter-type=ALWAYS
          data-element=CM_TCH_STAT, filter=data-filter-type=ALWAYS
          data-element=CameraDisplaySts2, filter=data-filter-type=ALWAYS
      RpToSwcSafeFD14Rx: required-interface=IF_FromComSafeFD14Rx
        required-com-specs:
          data-element=FD14_ACC_Systemsts, filter=data-filter-type=ALWAYS, init-value=0
          data-element=FD14_Brk_Stat, filter=data-filter-type=ALWAYS, init-value=0
          data-element=FD14_BrkPdl_Stat, filter=data-filter-type=ALWAYS, init-value=3
          data-element=FD14_BrkTrq, filter=data-filter-type=ALWAYS, init-value=32767
          data-element=FD14_BrkTrq_Driver, filter=data-filter-type=ALWAYS, init-value=32767
          data-element=FD14_BSM_THA_Brk_Resp, filter=data-filter-type=ALWAYS, init-value=0
          data-element=FD14_EPBSts, filter=data-filter-type=ALWAYS, init-value=0
          data-element=FD14_EPS_HandsOnRecognition, filter=data-filter-type=ALWAYS, init-value=0
          data-element=FD14_ESC_TRSC_Brk_Resp, filter=data-filter-type=ALWAYS, init-value=0
          data-element=FD14_ExternalBrkRequestsDisabled, filter=data-filter-type=ALWAYS, init-value=0
          data-element=FD14_HAS_Status, filter=data-filter-type=ALWAYS, init-value=0
          data-element=FD14_LatAcceleration_BSM, filter=data-filter-type=ALWAYS, init-value=4095
          data-element=FD14_LatAccelerationFailSts_BSM, filter=data-filter-type=ALWAYS, init-value=0
          data-element=FD14_LatAccelerationOffset_BSM, filter=data-filter-type=ALWAYS, init-value=255
          data-element=FD14_LHF_FastPulseCounter, filter=data-filter-type=ALWAYS, init-value=0
          data-element=FD14_LHF_Spin, filter=data-filter-type=ALWAYS, init-value=0
          data-element=FD14_LHF_WheelSensorFailSts, filter=data-filter-type=ALWAYS, init-value=0
          data-element=FD14_LHFWheelSpeed, filter=data-filter-type=ALWAYS, init-value=0
          data-element=FD14_LHR_FastPulseCounter, filter=data-filter-type=ALWAYS, init-value=0
          data-element=FD14_LHR_Spin, filter=data-filter-type=ALWAYS, init-value=0
          data-element=FD14_LHR_WheelSensorFailSts, filter=data-filter-type=ALWAYS, init-value=0
          data-element=FD14_LHRWheelSpeed, filter=data-filter-type=ALWAYS, init-value=0
          data-element=FD14_LongAcceleration_BSM, filter=data-filter-type=ALWAYS, init-value=4095
          data-element=FD14_LongAccelerationFailSts_BSM, filter=data-filter-type=ALWAYS, init-value=0
          data-element=FD14_LongAccelerationOffset_BSM, filter=data-filter-type=ALWAYS, init-value=255
          data-element=FD14_LwsAngle, filter=data-filter-type=ALWAYS, init-value=0
          data-element=FD14_LwsAngleType, filter=data-filter-type=ALWAYS, init-value=0
          data-element=FD14_LwsSpeed, filter=data-filter-type=ALWAYS, init-value=0
          data-element=FD14_PAM_Brk_Rq_RspSts, filter=data-filter-type=ALWAYS, init-value=0
          data-element=FD14_ParkingGearShiftReq_BSM, filter=data-filter-type=ALWAYS, init-value=0
          data-element=FD14_ParkingInterventionSts, filter=data-filter-type=ALWAYS, init-value=0
          data-element=FD14_REF_VEH_SPEED, filter=data-filter-type=ALWAYS, init-value=1023
          data-element=FD14_RHF_FastPulseCounter, filter=data-filter-type=ALWAYS, init-value=0
          data-element=FD14_RHF_Spin, filter=data-filter-type=ALWAYS, init-value=0
          data-element=FD14_RHF_WheelSensorFailSts, filter=data-filter-type=ALWAYS, init-value=0
          data-element=FD14_RHFWheelSpeed, filter=data-filter-type=ALWAYS, init-value=0
          data-element=FD14_RHR_FastPulseCounter, filter=data-filter-type=ALWAYS, init-value=0
          data-element=FD14_RHR_Spin, filter=data-filter-type=ALWAYS, init-value=0
          data-element=FD14_RHR_WheelSensorFailSts, filter=data-filter-type=ALWAYS, init-value=0
          data-element=FD14_RHRWheelSpeed, filter=data-filter-type=ALWAYS, init-value=0
          data-element=FD14_Slope, filter=data-filter-type=ALWAYS, init-value=0
          data-element=FD14_SPM_Lat_Ctrl_ResponseSts, filter=data-filter-type=ALWAYS, init-value=0
          data-element=FD14_Steering_Column_Torque, filter=data-filter-type=ALWAYS, init-value=0
          data-element=FD14_VehicleSpeedVSOSig, filter=data-filter-type=ALWAYS, init-value=0
          data-element=FD14_VehicleSpeedVSOSig_B2, filter=data-filter-type=ALWAYS, init-value=0
          data-element=FD14_VehicleStandStillSts, filter=data-filter-type=ALWAYS, init-value=1
          data-element=FD14_YawRate_BSM, filter=data-filter-type=ALWAYS, init-value=4095
          data-element=FD14_YawRateFailSts_BSM, filter=data-filter-type=ALWAYS, init-value=0
          data-element=FD14_ESS_ENG_ST_W, filter=data-filter-type=ALWAYS
          data-element=FD14_EngineSts_W, filter=data-filter-type=ALWAYS
          data-element=FD14_ECM_TRSC_Resp, filter=data-filter-type=ALWAYS
          data-element=FD14_ECM_THA_Resp, filter=data-filter-type=ALWAYS
          data-element=FD14_PdlPosActual, filter=data-filter-type=ALWAYS
          data-element=FD14_THA_SteeringTouchStat, filter=data-filter-type=ALWAYS
          data-element=FD14_EPS_THA_SteeringTorqueResp, filter=data-filter-type=ALWAYS
          data-element=FD14_EPS_THA_DriverTorqueOverride, filter=data-filter-type=ALWAYS
          data-element=FD14_EPS_SteeringTouq_Resp, filter=data-filter-type=ALWAYS
          data-element=FD14_EPS_SteeringTouchStat, filter=data-filter-type=ALWAYS
      RpToSwcFD14Rx: required-interface=IF_FromComFD14Rx
        required-com-specs:
          data-element=FD14_Accel_Pedal_Override, filter=data-filter-type=ALWAYS, init-value=0
          data-element=FD14_DriverReq_AxleTrq_Enabled_BSM, filter=data-filter-type=ALWAYS, init-value=0
          data-element=FD14_PPPA_TrqEnblRq_Allowed, filter=data-filter-type=ALWAYS, init-value=0
    provide port PpToComFD02Tx: provided-interface=IF_ToComFD02Tx
      provided-com-specs:
        data-element=CurrentCanNMState_FD02_PAM, init-value=0
        data-element=CurrentFailSts_FD02_PAM, init-value=0
        data-element=DES_FD02_PAM, init-value=0
        data-element=Digit_{01..11}_PAM, init-value=0
        data-element=EOL_FD02_PAM, init-value=0
        data-element=GenericFailSts_FD02_PAM, init-value=0
        {data-element=N_PDU, init-value=[rule-based-values={rule=FILL_UNTIL_END, rule-arguments=0}]}
        data-element=PreviousCanNMState_FD02_PAM, init-value=0
        {data-element=StayActiveSource_FD02_PAM, init-value=[rule-based-values={rule=FILL_UNTIL_END, rule-arguments=0}]}
        data-element=THA_EPB_Req, init-value=0
        data-element=THA_Speed_Limit, init-value=0
        data-element=THA_SpeedLimit_Req, init-value=0
        data-element=THA_STAT, init-value=0
        data-element=THA_SteeringDamping, init-value=78.125
        data-element=THA_SteeringTorqueInfo, init-value=0
        data-element=THA_SteeringTorqueReq, init-value=0
        data-element=Trailer_Angle, init-value=0
        data-element=Trailer_Angle_Sign, init-value=0
        data-element=Trailer_Calibration, init-value=0
        data-element=TrlrHitchLight_Cntrl, init-value=0
        data-element=TRSC_PopupDisp_Info, init-value=0
        data-element=TRSC_SpeedLimit_Req, init-value=0
        data-element=TRSC_STAT, init-value=1
        data-element=TRSC_SteeringDamping, init-value=100
        data-element=TRSC_SteeringTorqueInfo, init-value=0
        data-element=TRSC_SteeringTorqueReq, init-value=0
        data-element=TRSC_VehicleStop_Req, init-value=3
        data-element=TRSCMoreCamRQSts, init-value=0
        data-element=WakeupSource_FD02_PAM, init-value=0
        data-element=TRSC_PopupDisp_Info2, init-value=0
    require port RpPlantMode: nonqueued-receiver-com-spec{data-element=Status, filter=data-filter-type=ALWAYS}, required-interface=IF_PlantMode
    require port Dem_EnableCondition9: client-com-spec=SetEnableCondition, required-interface=EnableCondition
    provide port PpClearDTCSettingStatus: server-com-spec{operation=ClearDTCSettingStatus, queue-length=1}, provided-interface=IF_ClearDTCSettingStatus
    require port R_DtcData_QM: required-interface=P_DtcData_SR
      required-com-specs:
        data-element=Data_DtcAddData_QM, filter=data-filter-type=ALWAYS
        data-element=Data_DtcStatus_QM, filter=data-filter-type=ALWAYS
    require port R_DtcData_B: required-interface=P_DtcData_SR
      required-com-specs:
        data-element=Data_DtcAddData_B, filter=data-filter-type=ALWAYS
        data-element=Data_DtcStatus_B, filter=data-filter-type=ALWAYS
    15 x provide port, all with server-com-spec{operation=ReadData, queue-length=1}:
      CSDataServices_Data_OccurrenceCounter_Camera_Occlusion: provided-interface=CSDataServices_Data_OccurrenceCounter_Camera_Occlusion
      CSDataServices_Data_OccurrenceCounter_Current_Gear: provided-interface=CSDataServices_Data_OccurrenceCounter_Current_Gear
      CSDataServices_Data_OccurrenceCounter_DisplayStatus: provided-interface=CSDataServices_Data_OccurrenceCounter_DisplayStatus
      CSDataServices_Data_OccurrenceCounter_Door_Status: provided-interface=CSDataServices_Data_OccurrenceCounter_Door_Status
      CSDataServices_Data_OccurrenceCounter_ECU_Voltage: provided-interface=CSDataServices_Data_OccurrenceCounter_ECU_Voltage
      CSDataServices_Data_OccurrenceCounter_External_Temperature: provided-interface=CSDataServices_Data_OccurrenceCounter_External_Temperature
      CSDataServices_Data_OccurrenceCounter_Odometer_Value: provided-interface=CSDataServices_Data_OccurrenceCounter_Odometer_Value
      CSDataServices_Data_OccurrenceCounter_THA_state: provided-interface=CSDataServices_Data_OccurrenceCounter_THA_state
      CSDataServices_Data_OccurrenceCounter_Touch_Screen_Status: provided-interface=CSDataServices_Data_OccurrenceCounter_Touch_Screen_Status
      CSDataServices_Data_OccurrenceCounter_Supplier_Internal_Code: provided-interface=CSDataServices_Data_OccurrenceCounter_Supplier_Internal_Code
      CSDataServices_Data_OccurrenceCounter_TireLines: provided-interface=CSDataServices_Data_OccurrenceCounter_TireLines
      CSDataServices_Data_OccurrenceCounter_Touch_Screen_X_Coordinate: provided-interface=CSDataServices_Data_OccurrenceCounter_Touch_Screen_X_Coordinate
      CSDataServices_Data_OccurrenceCounter_Touch_Screen_Y_Coordinate: provided-interface=CSDataServices_Data_OccurrenceCounter_Touch_Screen_Y_Coordinate
      CSDataServices_Data_OccurrenceCounter_TRSC_Stat: provided-interface=CSDataServices_Data_OccurrenceCounter_TRSC_Stat
      CSDataServices_Data_OccurrenceCounter_Vehicle_Speed: provided-interface=CSDataServices_Data_OccurrenceCounter_Vehicle_Speed
    8 x require port:
      RpCalDataProviderNvmData: nonqueued-receiver-com-spec{data-element=CalData_mcu1_0, filter=data-filter-type=ALWAYS}, required-interface=IF_SWC_CalDataProvider_MCU1_0_Nvm_Data
      RpToSwcFD02Tx: required-interface=IF_ToSwcFD02Tx
        required-com-specs:
          data-element=CurrentCanNMState_FD02_PAM, filter=data-filter-type=ALWAYS, init-value=0
          data-element=CurrentFailSts_FD02_PAM, filter=data-filter-type=ALWAYS, init-value=0
          data-element=DES_FD02_PAM, filter=data-filter-type=ALWAYS, init-value=0
          data-element=Digit_{01..11}_PAM, filter=data-filter-type=ALWAYS, init-value=0
          data-element=EOL_FD02_PAM, filter=data-filter-type=ALWAYS, init-value=0
          data-element=GenericFailSts_FD02_PAM, filter=data-filter-type=ALWAYS, init-value=0
          {data-element=N_PDU, filter=data-filter-type=ALWAYS, init-value=[rule-based-values={rule=FILL_UNTIL_END, rule-arguments=0}]}
          data-element=PreviousCanNMState_FD02_PAM, filter=data-filter-type=ALWAYS, init-value=0
          {data-element=StayActiveSource_FD02_PAM, filter=data-filter-type=ALWAYS, init-value=[rule-based-values={rule=FILL_UNTIL_END, rule-arguments=0}]}
          data-element=THA_EPB_Req, filter=data-filter-type=ALWAYS, init-value=0
          data-element=THA_Speed_Limit, filter=data-filter-type=ALWAYS, init-value=0
          data-element=THA_SpeedLimit_Req, filter=data-filter-type=ALWAYS, init-value=0
          data-element=THA_STAT, filter=data-filter-type=ALWAYS, init-value=0
          data-element=THA_SteeringDamping, filter=data-filter-type=ALWAYS, init-value=78.125
          data-element=THA_SteeringTorqueInfo, filter=data-filter-type=ALWAYS, init-value=0
          data-element=THA_SteeringTorqueReq, filter=data-filter-type=ALWAYS, init-value=0
          data-element=Trailer_Angle, filter=data-filter-type=ALWAYS, init-value=0
          data-element=Trailer_Angle_Sign, filter=data-filter-type=ALWAYS, init-value=0
          data-element=Trailer_Calibration, filter=data-filter-type=ALWAYS, init-value=0
          data-element=TrlrHitchLight_Cntrl, filter=data-filter-type=ALWAYS, init-value=0
          data-element=TRSC_PopupDisp_Info, filter=data-filter-type=ALWAYS, init-value=0
          data-element=TRSC_SpeedLimit_Req, filter=data-filter-type=ALWAYS, init-value=0
          data-element=TRSC_STAT, filter=data-filter-type=ALWAYS, init-value=1
          data-element=TRSC_SteeringDamping, filter=data-filter-type=ALWAYS, init-value=100
          data-element=TRSC_SteeringTorqueInfo, filter=data-filter-type=ALWAYS, init-value=0
          data-element=TRSC_SteeringTorqueReq, filter=data-filter-type=ALWAYS, init-value=0
          data-element=TRSC_VehicleStop_Req, filter=data-filter-type=ALWAYS, init-value=3
          data-element=TRSCMoreCamRQSts, filter=data-filter-type=ALWAYS, init-value=0
          data-element=WakeupSource_FD02_PAM, filter=data-filter-type=ALWAYS, init-value=0
          data-element=TRSC_PopupDisp_Info2, filter=data-filter-type=ALWAYS
      RpToSwcFD14Tx: required-interface=IF_ToSwcFD14Tx
        required-com-specs:
          data-element=FD14_TRSC_VehicleStop_Req, filter=data-filter-type=ALWAYS
          data-element=FD14_TRSC_SteeringTorqueReq, filter=data-filter-type=ALWAYS
          data-element=FD14_TRSC_SteeringTorqueInfo, filter=data-filter-type=ALWAYS
          data-element=FD14_TRSC_SteeringDamping, filter=data-filter-type=ALWAYS
          data-element=FD14_TRSC_STAT, filter=data-filter-type=ALWAYS
          data-element=FD14_TRSC_SpeedLimit_Req, filter=data-filter-type=ALWAYS
          data-element=FD14_THA_SteeringTorqueReq, filter=data-filter-type=ALWAYS
          data-element=FD14_THA_SteeringTorqueInfo, filter=data-filter-type=ALWAYS
          data-element=FD14_THA_SteeringDamping, filter=data-filter-type=ALWAYS
          data-element=FD14_THA_STAT, filter=data-filter-type=ALWAYS
          data-element=FD14_THA_SpeedLimit_Req, filter=data-filter-type=ALWAYS
          data-element=FD14_THA_Speed_Limit, filter=data-filter-type=ALWAYS
          data-element=FD14_THA_EPB_Req, filter=data-filter-type=ALWAYS
      RpToSwcSafeFD14Tx: required-interface=IF_ToSwcSafeFD14Tx
        required-com-specs:
          data-element=FD14_TorqueOverlaySteeringReq_SPM, filter=data-filter-type=ALWAYS
          data-element=FD14_SPM_Lat_Ctrl_RequestSts, filter=data-filter-type=ALWAYS
          data-element=FD14_RR_PAM_Dist, filter=data-filter-type=ALWAYS
          data-element=FD14_RR_PAM_Brk_RqSts, filter=data-filter-type=ALWAYS
          data-element=FD14_PPPA_TargetDistance, filter=data-filter-type=ALWAYS
          data-element=FD14_PPPA_StandstillRqst, filter=data-filter-type=ALWAYS
          data-element=FD14_PPPA_MaxSpeed, filter=data-filter-type=ALWAYS
          data-element=FD14_PPPA_JerkDecelMin, filter=data-filter-type=ALWAYS
          data-element=FD14_PPPA_JerkDecelMax, filter=data-filter-type=ALWAYS
          data-element=FD14_PPPA_JerkAccelMin, filter=data-filter-type=ALWAYS
          data-element=FD14_PPPA_JerkAccelMax, filter=data-filter-type=ALWAYS
          data-element=FD14_PPPA_Interface_BSM, filter=data-filter-type=ALWAYS
          data-element=FD14_PPPA_DecelMin, filter=data-filter-type=ALWAYS
          data-element=FD14_PPPA_DecelMax, filter=data-filter-type=ALWAYS
          data-element=FD14_PPPA_AccelMin, filter=data-filter-type=ALWAYS
          data-element=FD14_PPPA_AccelMax, filter=data-filter-type=ALWAYS
          data-element=FD14_ParkingGearShiftReq, filter=data-filter-type=ALWAYS
          data-element=FD14_ManoeuvrePhase, filter=data-filter-type=ALWAYS
          data-element=FD14_Segment_8_Y2, filter=data-filter-type=ALWAYS
          data-element=FD14_Segment_8_Y1, filter=data-filter-type=ALWAYS
          data-element=FD14_Segment_8_X2, filter=data-filter-type=ALWAYS
          data-element=FD14_Segment_8_X1, filter=data-filter-type=ALWAYS
          data-element=FD14_Segment_8_ID, filter=data-filter-type=ALWAYS
          data-element=FD14_Segment_8_Confidence, filter=data-filter-type=ALWAYS
          data-element=FD14_Segment_7_Y2, filter=data-filter-type=ALWAYS
          data-element=FD14_Segment_7_Y1, filter=data-filter-type=ALWAYS
          data-element=FD14_Segment_7_X2, filter=data-filter-type=ALWAYS
          data-element=FD14_Segment_7_X1, filter=data-filter-type=ALWAYS
          data-element=FD14_Segment_7_ID, filter=data-filter-type=ALWAYS
          data-element=FD14_Segment_7_Confidence, filter=data-filter-type=ALWAYS
          data-element=FD14_Segment_6_Y2, filter=data-filter-type=ALWAYS
          data-element=FD14_Segment_6_Y1, filter=data-filter-type=ALWAYS
          data-element=FD14_Segment_6_X2, filter=data-filter-type=ALWAYS
          data-element=FD14_Segment_6_X1, filter=data-filter-type=ALWAYS
          data-element=FD14_Segment_6_ID, filter=data-filter-type=ALWAYS
          data-element=FD14_Segment_6_Confidence, filter=data-filter-type=ALWAYS
          data-element=FD14_Segment_5_Y2, filter=data-filter-type=ALWAYS
          data-element=FD14_Segment_5_Y1, filter=data-filter-type=ALWAYS
          data-element=FD14_Segment_5_X2, filter=data-filter-type=ALWAYS
          data-element=FD14_Segment_5_X1, filter=data-filter-type=ALWAYS
          data-element=FD14_Segment_5_ID, filter=data-filter-type=ALWAYS
          data-element=FD14_Segment_5_Confidence, filter=data-filter-type=ALWAYS
          data-element=FD14_Segment_4_Y2, filter=data-filter-type=ALWAYS
          data-element=FD14_Segment_4_Y1, filter=data-filter-type=ALWAYS
          data-element=FD14_Segment_4_X2, filter=data-filter-type=ALWAYS
          data-element=FD14_Segment_4_X1, filter=data-filter-type=ALWAYS
          data-element=FD14_Segment_4_ID, filter=data-filter-type=ALWAYS
          data-element=FD14_Segment_4_Confidence, filter=data-filter-type=ALWAYS
          data-element=FD14_Segment_3_Y2, filter=data-filter-type=ALWAYS
          data-element=FD14_Segment_3_Y1, filter=data-filter-type=ALWAYS
          data-element=FD14_Segment_3_X2, filter=data-filter-type=ALWAYS
          data-element=FD14_Segment_3_X1, filter=data-filter-type=ALWAYS
          data-element=FD14_Segment_3_ID, filter=data-filter-type=ALWAYS
          data-element=FD14_Segment_3_Confidence, filter=data-filter-type=ALWAYS
          data-element=FD14_Segment_2_Y2, filter=data-filter-type=ALWAYS
          data-element=FD14_Segment_2_Y1, filter=data-filter-type=ALWAYS
          data-element=FD14_Segment_2_X2, filter=data-filter-type=ALWAYS
          data-element=FD14_Segment_2_X1, filter=data-filter-type=ALWAYS
          data-element=FD14_Segment_2_ID, filter=data-filter-type=ALWAYS
          data-element=FD14_Segment_2_Confidence, filter=data-filter-type=ALWAYS
          data-element=FD14_Segment_1_Y2, filter=data-filter-type=ALWAYS
          data-element=FD14_Segment_1_Y1, filter=data-filter-type=ALWAYS
          data-element=FD14_Segment_1_X2, filter=data-filter-type=ALWAYS
          data-element=FD14_Segment_1_X1, filter=data-filter-type=ALWAYS
          data-element=FD14_Segment_1_ID, filter=data-filter-type=ALWAYS
          data-element=FD14_Segment_1_Confidence, filter=data-filter-type=ALWAYS
          data-element=FD14_Reserved_for_functional_safety, filter=data-filter-type=ALWAYS
          data-element=FD14_ParkingManeuverActive, filter=data-filter-type=ALWAYS
          data-element=FD14_MAC_ADAS_FD_LANES_2, filter=data-filter-type=ALWAYS
          data-element=FD14_MAC_ADAS_FD_LANES_1, filter=data-filter-type=ALWAYS
          data-element=FD14_Line_4_Type, filter=data-filter-type=ALWAYS
          data-element=FD14_Line_4_Start_Range, filter=data-filter-type=ALWAYS
          data-element=FD14_Line_4_Offset, filter=data-filter-type=ALWAYS
          data-element=FD14_Line_4_Heading, filter=data-filter-type=ALWAYS
          data-element=FD14_Line_4_End_Range, filter=data-filter-type=ALWAYS
          data-element=FD14_Line_4_Curvature_Rate, filter=data-filter-type=ALWAYS
          data-element=FD14_Line_4_Curvature, filter=data-filter-type=ALWAYS
          data-element=FD14_Line_4_Confidence, filter=data-filter-type=ALWAYS
          data-element=FD14_Line_3_Type, filter=data-filter-type=ALWAYS
          data-element=FD14_Line_3_Start_Range, filter=data-filter-type=ALWAYS
          data-element=FD14_Line_3_Offset, filter=data-filter-type=ALWAYS
          data-element=FD14_Line_3_Heading, filter=data-filter-type=ALWAYS
          data-element=FD14_Line_3_End_Range, filter=data-filter-type=ALWAYS
          data-element=FD14_Line_3_Curvature_Rate, filter=data-filter-type=ALWAYS
          data-element=FD14_Line_3_Curvature, filter=data-filter-type=ALWAYS
          data-element=FD14_Line_3_Confidence, filter=data-filter-type=ALWAYS
          data-element=FD14_Line_2_Type, filter=data-filter-type=ALWAYS
          data-element=FD14_Line_2_Start_Range, filter=data-filter-type=ALWAYS
          data-element=FD14_Line_2_Offset, filter=data-filter-type=ALWAYS
          data-element=FD14_Line_2_Heading, filter=data-filter-type=ALWAYS
          data-element=FD14_Line_2_End_Range, filter=data-filter-type=ALWAYS
          data-element=FD14_Line_2_Curvature_Rate, filter=data-filter-type=ALWAYS
          data-element=FD14_Line_2_Curvature, filter=data-filter-type=ALWAYS
          data-element=FD14_Line_2_Confidence, filter=data-filter-type=ALWAYS
          data-element=FD14_Line_1_Type, filter=data-filter-type=ALWAYS
          data-element=FD14_Line_1_Start_Range, filter=data-filter-type=ALWAYS
          data-element=FD14_Line_1_Offset, filter=data-filter-type=ALWAYS
          data-element=FD14_Line_1_Heading, filter=data-filter-type=ALWAYS
          data-element=FD14_Line_1_End_Range, filter=data-filter-type=ALWAYS
          data-element=FD14_Line_1_Curvature_Rate, filter=data-filter-type=ALWAYS
          data-element=FD14_Line_1_Curvature, filter=data-filter-type=ALWAYS
          data-element=FD14_Line_1_Confidence, filter=data-filter-type=ALWAYS
          data-element=FD14_Health_Lane_Detection, filter=data-filter-type=ALWAYS
          data-element=FD14_Health_Front_Object_Detection, filter=data-filter-type=ALWAYS
          data-element=FD14_Frame_Index_Lanes_2, filter=data-filter-type=ALWAYS
          data-element=FD14_Frame_Index_Lanes_1, filter=data-filter-type=ALWAYS
          data-element=FD14_FOD_Confidence, filter=data-filter-type=ALWAYS
          data-element=FD14_Cntr_ADAS_FD_LANES_2, filter=data-filter-type=ALWAYS
          data-element=FD14_Cntr_ADAS_FD_LANES_1, filter=data-filter-type=ALWAYS
          data-element=FD14_Camera_Status, filter=data-filter-type=ALWAYS
      RpToSwcSafeFD02Tx: required-interface=IF_ToSwcSafeFD02Tx
        required-com-specs:
          data-element=TRSC_LED_Stat, filter=data-filter-type=ALWAYS
          data-element=SPMSystemFault, filter=data-filter-type=ALWAYS
          data-element=SPMFailSts, filter=data-filter-type=ALWAYS
          data-element=SPMControlSts, filter=data-filter-type=ALWAYS
          data-element=SPM_Screen_Rqst, filter=data-filter-type=ALWAYS
          data-element=SPM_LedControlSts, filter=data-filter-type=ALWAYS
          data-element=RR_PAM_StopControlSts, filter=data-filter-type=ALWAYS
          data-element=RR_PAM_Dist, filter=data-filter-type=ALWAYS
          data-element=RR_PAM_Brk_RqSts, filter=data-filter-type=ALWAYS
          data-element=RearSensorSts, filter=data-filter-type=ALWAYS
          data-element=PPPA_TurnIndicatorRqst, filter=data-filter-type=ALWAYS
          data-element=ParkingManeuverActive, filter=data-filter-type=ALWAYS
          data-element=PAMSystemFault, filter=data-filter-type=ALWAYS
          data-element=PAM_Volume, filter=data-filter-type=ALWAYS
          data-element=PAM_PopUpRqst, filter=data-filter-type=ALWAYS
          data-element=PAM_Off_Status_2BT, filter=data-filter-type=ALWAYS
          data-element=PAM_Off_Status, filter=data-filter-type=ALWAYS
          data-element=PAM_LedControlSts, filter=data-filter-type=ALWAYS
          data-element=PAM_CHIME_TYPE, filter=data-filter-type=ALWAYS
          data-element=PAM_CHIME_REP_RATESts, filter=data-filter-type=ALWAYS
          data-element=MoreCamsRQSts, filter=data-filter-type=ALWAYS
          data-element=ImageDefeatRQSts, filter=data-filter-type=ALWAYS
          data-element=HMICode, filter=data-filter-type=ALWAYS
          data-element=Graphic_RHR, filter=data-filter-type=ALWAYS
          data-element=Graphic_RHF, filter=data-filter-type=ALWAYS
          data-element=Graphic_LHR, filter=data-filter-type=ALWAYS
          data-element=Graphic_LHF, filter=data-filter-type=ALWAYS
          data-element=Graphic_CHR, filter=data-filter-type=ALWAYS
          data-element=Graphic_CHF, filter=data-filter-type=ALWAYS
          data-element=FT_PAM_LedControlSts, filter=data-filter-type=ALWAYS
          data-element=FrontSensorSts, filter=data-filter-type=ALWAYS
          data-element=DisplayView2, filter=data-filter-type=ALWAYS
          data-element=ChimeActivation_RHR, filter=data-filter-type=ALWAYS
          data-element=ChimeActivation_RHF, filter=data-filter-type=ALWAYS
          data-element=ChimeActivation_LHR, filter=data-filter-type=ALWAYS
          data-element=ChimeActivation_LHF, filter=data-filter-type=ALWAYS
          data-element=AUXCamsRQSts, filter=data-filter-type=ALWAYS
          data-element=Alert_RHR, filter=data-filter-type=ALWAYS
          data-element=Alert_RHF, filter=data-filter-type=ALWAYS
          data-element=Alert_LHR, filter=data-filter-type=ALWAYS
          data-element=Alert_LHF, filter=data-filter-type=ALWAYS
          data-element=Alert_CHR, filter=data-filter-type=ALWAYS
          data-element=Alert_CHF, filter=data-filter-type=ALWAYS
          data-element=MAC_ADAS_FD_LANES_2, filter=data-filter-type=ALWAYS
          data-element=MAC_ADAS_FD_LANES_1, filter=data-filter-type=ALWAYS
          data-element=Line_4_Type, filter=data-filter-type=ALWAYS
          data-element=Line_4_Start_Range, filter=data-filter-type=ALWAYS
          data-element=Line_4_Offset, filter=data-filter-type=ALWAYS
          data-element=Line_4_Heading, filter=data-filter-type=ALWAYS
          data-element=Line_4_End_Range, filter=data-filter-type=ALWAYS
          data-element=Line_4_Curvature_Rate, filter=data-filter-type=ALWAYS
          data-element=Line_4_Curvature, filter=data-filter-type=ALWAYS
          data-element=Line_4_Confidence, filter=data-filter-type=ALWAYS
          data-element=Line_3_Type, filter=data-filter-type=ALWAYS
          data-element=Line_3_Start_Range, filter=data-filter-type=ALWAYS
          data-element=Line_3_Offset, filter=data-filter-type=ALWAYS
          data-element=Line_3_Heading, filter=data-filter-type=ALWAYS
          data-element=Line_3_End_Range, filter=data-filter-type=ALWAYS
          data-element=Line_3_Curvature_Rate, filter=data-filter-type=ALWAYS
          data-element=Line_3_Curvature, filter=data-filter-type=ALWAYS
          data-element=Line_3_Confidence, filter=data-filter-type=ALWAYS
          data-element=Line_2_Type, filter=data-filter-type=ALWAYS
          data-element=Line_2_Start_Range, filter=data-filter-type=ALWAYS
          data-element=Line_2_Offset, filter=data-filter-type=ALWAYS
          data-element=Line_2_Heading, filter=data-filter-type=ALWAYS
          data-element=Line_2_End_Range, filter=data-filter-type=ALWAYS
          data-element=Line_2_Curvature_Rate, filter=data-filter-type=ALWAYS
          data-element=Line_2_Curvature, filter=data-filter-type=ALWAYS
          data-element=Line_2_Confidence, filter=data-filter-type=ALWAYS
          data-element=Line_1_Type, filter=data-filter-type=ALWAYS
          data-element=Line_1_Start_Range, filter=data-filter-type=ALWAYS
          data-element=Line_1_Offset, filter=data-filter-type=ALWAYS
          data-element=Line_1_Heading, filter=data-filter-type=ALWAYS
          data-element=Line_1_End_Range, filter=data-filter-type=ALWAYS
          data-element=Line_1_Curvature_Rate, filter=data-filter-type=ALWAYS
          data-element=Line_1_Curvature, filter=data-filter-type=ALWAYS
          data-element=Line_1_Confidence, filter=data-filter-type=ALWAYS
          data-element=Health_Lane_Detection, filter=data-filter-type=ALWAYS
          data-element=Health_Front_Object_Detection, filter=data-filter-type=ALWAYS
          data-element=Frame_Index_Lanes_2, filter=data-filter-type=ALWAYS
          data-element=Frame_Index_Lanes_1, filter=data-filter-type=ALWAYS
          data-element=FOD_Confidence, filter=data-filter-type=ALWAYS
          data-element=Cntr_ADAS_FD_LANES_2, filter=data-filter-type=ALWAYS
          data-element=Cntr_ADAS_FD_LANES_1, filter=data-filter-type=ALWAYS
          data-element=Camera_Status, filter=data-filter-type=ALWAYS
          data-element=Segment_8_Y2, filter=data-filter-type=ALWAYS
          data-element=Segment_8_Y1, filter=data-filter-type=ALWAYS
          data-element=Segment_8_X2, filter=data-filter-type=ALWAYS
          data-element=Segment_8_X1, filter=data-filter-type=ALWAYS
          data-element=Segment_8_ID, filter=data-filter-type=ALWAYS
          data-element=Segment_8_Confidence, filter=data-filter-type=ALWAYS
          data-element=Segment_7_Y2, filter=data-filter-type=ALWAYS
          data-element=Segment_7_Y1, filter=data-filter-type=ALWAYS
          data-element=Segment_7_X2, filter=data-filter-type=ALWAYS
          data-element=Segment_7_X1, filter=data-filter-type=ALWAYS
          data-element=Segment_7_ID, filter=data-filter-type=ALWAYS
          data-element=Segment_7_Confidence, filter=data-filter-type=ALWAYS
          data-element=Segment_6_Y2, filter=data-filter-type=ALWAYS
          data-element=Segment_6_Y1, filter=data-filter-type=ALWAYS
          data-element=Segment_6_X2, filter=data-filter-type=ALWAYS
          data-element=Segment_6_X1, filter=data-filter-type=ALWAYS
          data-element=Segment_6_ID, filter=data-filter-type=ALWAYS
          data-element=Segment_6_Confidence, filter=data-filter-type=ALWAYS
          data-element=Segment_5_Y2, filter=data-filter-type=ALWAYS
          data-element=Segment_5_Y1, filter=data-filter-type=ALWAYS
          data-element=Segment_5_X2, filter=data-filter-type=ALWAYS
          data-element=Segment_5_X1, filter=data-filter-type=ALWAYS
          data-element=Segment_5_ID, filter=data-filter-type=ALWAYS
          data-element=Segment_5_Confidence, filter=data-filter-type=ALWAYS
          data-element=Segment_4_Y2, filter=data-filter-type=ALWAYS
          data-element=Segment_4_Y1, filter=data-filter-type=ALWAYS
          data-element=Segment_4_X2, filter=data-filter-type=ALWAYS
          data-element=Segment_4_X1, filter=data-filter-type=ALWAYS
          data-element=Segment_4_ID, filter=data-filter-type=ALWAYS
          data-element=Segment_4_Confidence, filter=data-filter-type=ALWAYS
          data-element=Segment_3_Y2, filter=data-filter-type=ALWAYS
          data-element=Segment_3_Y1, filter=data-filter-type=ALWAYS
          data-element=Segment_3_X2, filter=data-filter-type=ALWAYS
          data-element=Segment_3_X1, filter=data-filter-type=ALWAYS
          data-element=Segment_3_ID, filter=data-filter-type=ALWAYS
          data-element=Segment_3_Confidence, filter=data-filter-type=ALWAYS
          data-element=Segment_2_Y2, filter=data-filter-type=ALWAYS
          data-element=Segment_2_Y1, filter=data-filter-type=ALWAYS
          data-element=Segment_2_X2, filter=data-filter-type=ALWAYS
          data-element=Segment_2_X1, filter=data-filter-type=ALWAYS
          data-element=Segment_2_ID, filter=data-filter-type=ALWAYS
          data-element=Segment_2_Confidence, filter=data-filter-type=ALWAYS
          data-element=Segment_1_Y2, filter=data-filter-type=ALWAYS
          data-element=Segment_1_Y1, filter=data-filter-type=ALWAYS
          data-element=Segment_1_X2, filter=data-filter-type=ALWAYS
          data-element=Segment_1_X1, filter=data-filter-type=ALWAYS
          data-element=Segment_1_ID, filter=data-filter-type=ALWAYS
          data-element=Segment_1_Confidence, filter=data-filter-type=ALWAYS
          data-element=Reserved_for_functional_safety, filter=data-filter-type=ALWAYS
      RpDLDOutput: nonqueued-receiver-com-spec{data-element=JobDLDOutput_t, filter=data-filter-type=ALWAYS}, required-interface=IF_DLDOutput
      RpErrors_B: nonqueued-receiver-com-spec{data-element=Errors_B, init-value=constant-reference=init_Errors_B}, required-interface=P_Errors_B_SR
      RpErrors_QM: nonqueued-receiver-com-spec{data-element=Errors_QM, init-value=constant-reference=init_Errors_QM}, required-interface=P_Errors_QM_SR
    4 x provide port, all with server-com-spec{operation=ReadData, queue-length=1}:
      CSDataServices_Data_OccurrenceCounter_Aging_Counter_ID: provided-interface=CSDataServices_Data_OccurrenceCounter_Aging_Counter_ID
      CSDataServices_Data_OccurrenceCounter_Frequency_Counter_ID: provided-interface=CSDataServices_Data_OccurrenceCounter_Frequency_Counter_ID
      CSDataServices_Data_OccurrenceCounter_Radio_Display_Status: provided-interface=CSDataServices_Data_OccurrenceCounter_Radio_Display_Status
      CSDataServices_Data_OccurrenceCounter_TRSKM_and_USS_status: provided-interface=CSDataServices_Data_OccurrenceCounter_TRSKM_and_USS_status
    require port RpAPSMPAOut: nonqueued-receiver-com-spec{data-element=TbAP_APSMPAOut_t, filter=data-filter-type=ALWAYS, init-value=fields=[IeAP_e_PAMFlt:0, IeAP_e_FrntRearParkSts:0, IeAP_e_FrntSensorActvSts:0, IeAP_e_RearSnsrActvSts:0]}, required-interface=IF_APSMPAOut
    require port RpEventDTC_P060200: required-interface=DiagnosticMonitor
      required-com-specs:
        SetEventStatus
        GetEventExtendedDataRecordEx
        GetEventFreezeFrameDataEx
        GetFaultDetectionCounter
        GetDTCOfEvent
        GetEventTested
        GetEventFailed
        GetEventStatus
        GetEventUdsStatus
        ResetEventDebounceStatus
        ResetEventStatus
    11 x provide port, all with server-com-spec{operation=ReadData, queue-length=1}:
      CSDataServices_Data_OccurrenceCounter_New_Bit_Field: provided-interface=CSDataServices_Data_OccurrenceCounter_New_Bit_Field
      CSDataServices_Data_OccurrenceCounter_LiftgateAjar: provided-interface=CSDataServices_Data_OccurrenceCounter_LiftgateAjar
      CSDataServices_Data_OccurrenceCounter_Calibration_Running: provided-interface=CSDataServices_Data_OccurrenceCounter_Calibration_Running
      CSDataServices_Data_OccurrenceCounter_Calibration_Pending: provided-interface=CSDataServices_Data_OccurrenceCounter_Calibration_Pending
      CSDataServices_Data_OccurrenceCounter_Calibration_Not_Started: provided-interface=CSDataServices_Data_OccurrenceCounter_Calibration_Not_Started
      CSDataServices_Data_OccurrenceCounter_Calibration_Aborted_Failed: provided-interface=CSDataServices_Data_OccurrenceCounter_Calibration_Aborted_Failed
      CSDataServices_Data_OccurrenceCounter_Calibrated_Successfully: provided-interface=CSDataServices_Data_OccurrenceCounter_Calibrated_Successfully
      CSDataServices_Data_OccurrenceCounter_Steering_Wheel_Angle: provided-interface=CSDataServices_Data_OccurrenceCounter_Steering_Wheel_Angle
      CSDataServices_Data_OccurrenceCounter_Reserved_1: provided-interface=CSDataServices_Data_OccurrenceCounter_Reserved_1
      CSDataServices_Data_OccurrenceCounter_Reserved: provided-interface=CSDataServices_Data_OccurrenceCounter_Reserved
      CSDataServices_Data_OccurrenceCounter_Cycles_to_Switch_off_the_Warning_Indication_ID: provided-interface=CSDataServices_Data_OccurrenceCounter_Cycles_to_Switch_off_the_Warning_Indication_ID
    provide/require port PRpDtcSettingClearFlagModeGrp: nonqueued-sender-com-spec{data-element=requestedMode, init-value=0}, nonqueued-receiver-com-spec{data-element=requestedMode, filter=data-filter-type=ALWAYS}, provided-required-interface=BswM_SRI_BswM_MSI_DtcSettingClearFlagModeGrp_BswM_MDGP_DtcSettingClearFlagModeGrp
    require port NvMService_AC3_SRBS_DTC_APARequestSts_PAMRequestSts: required-com-specs=[WriteBlock, SetRamBlockStatus, ReadBlock, InvalidateNvBlock, GetErrorStatus, EraseBlock], required-interface=NvMService_AC3_SRBS
    provide port PpDtcB12852AData: nonqueued-sender-com-spec{data-element=v_DtcData_u8, init-value=0}, provided-interface=IF_DtcB12852AData
    provide port CSDataServices_Data_OccurrenceCounter_Reserved_2: server-com-spec{operation=ReadData, queue-length=1}, provided-interface=CSDataServices_Data_OccurrenceCounter_Reserved_2
    provide/require port PpRpSnsrFnctnlTstFlg: nonqueued-sender-com-spec{data-element=SensorFunctionalTestFlag, init-value=0}, nonqueued-receiver-com-spec{data-element=SensorFunctionalTestFlag, filter=data-filter-type=ALWAYS}, provided-required-interface=IF_SnsrFnctnlTstFlg
    require port RpIpcTxData: client-com-spec=IPC_Write_v, required-interface=IF_IpcTxData
    provide port CSDataServices_Data_DID_0x1921_CombinedSignal: server-com-spec{operation=ReadData, queue-length=1}, provided-interface=CSDataServices_Data_DID_0x1921_CombinedSignal
    require port Dem_EnableCondition10: client-com-spec=SetEnableCondition, required-interface=EnableCondition
    behavior SWC_DTCMgr_InternalBehavior: data-type-mapping=DataTypeMappings_DEV, handle-termination-and-restart=NO-SUPPORT
      ar-typed-per-instance-memorys:
        data DTC_APARequestSts_PAMRequestSts_MirrorBlock: sw-calibration-access=READ-ONLY, type=uint8
      init event InitEvent: start-on-event=RE_DTCMgr_Init
      timing event TMT_RE_DTCMgr_Main: start-on-event=RE_DTCMgr_Main, period=0.01
      6 x operation invoked event:
        OIT_CSDataServices_Data_DID_0x1008_ECU_Life_Time_24_ReadData_CSDataServices_Data_DID_0x1008_ECU_Life_Time_24_ReadData: start-on-event=CSDataServices_Data_DID_0x1008_ECU_Life_Time_24_ReadData, operation=CSDataServices_Data_DID_0x1008_ECU_Life_Time_24.ReadData
        OIT_CSDataServices_Data_DID_0x1002_Vehicle_Speed_24_ReadData_CSDataServices_Data_DID_0x1002_Vehicle_Speed_24_ReadData: start-on-event=CSDataServices_Data_DID_0x1002_Vehicle_Speed_24_ReadData, operation=CSDataServices_Data_DID_0x1002_Vehicle_Speed_24.ReadData
        OIT_CSDataServices_Data_DID_0x1009_ECU_Time_Since_Ignition_ON_ReadData_CSDataServices_Data_DID_0x1009_ECU_Time_Since_Ign975E9003: start-on-event=CSDataServices_Data_DID_0x1009_ECU_Time_Since_Ignition_ON_ReadData, operation=CSDataServices_Data_DID_0x1009_ECU_Time_Since_Ignition_ON.ReadData
        OIT_CSDataServices_Data_DID_0x200a_Ignition_ON_Counter_24_ReadData_CSDataServices_Data_DID_0x200a_Ignition_ON_Counter_2498E7759A: start-on-event=CSDataServices_Data_DID_0x200a_Ignition_ON_Counter_24_ReadData, operation=CSDataServices_Data_DID_0x200a_Ignition_ON_Counter_24.ReadData
        OIT_CSDataServices_Data_DID_0x2001_Odometer_24_ReadData_CSDataServices_Data_DID_0x2001_Odometer_24_ReadData: start-on-event=CSDataServices_Data_DID_0x2001_Odometer_24_ReadData, operation=CSDataServices_Data_DID_0x2001_Odometer_24.ReadData
        OIT_CSDataServices_Data_DID_0x1004_Battery_Voltage_24_ReadData_CSDataServices_Data_DID_0x1004_Battery_Voltage_24_ReadData: start-on-event=CSDataServices_Data_DID_0x1004_Battery_Voltage_24_ReadData, operation=CSDataServices_Data_DID_0x1004_Battery_Voltage_24.ReadData
      data received event DRT_RE_DTCMgr_EtROEMessage_RoEMessageSRI_Data: start-on-event=RE_DTCMgr_EtROEMessage, data=RoEMessageSRI.Data
      33 x operation invoked event:
        OIT_RE_PpClearDTCSettingStatus_ClearDTCSettingStatus_PpClearDTCSettingStatus_ClearDTCSettingStatus: start-on-event=RE_ClearDTCSettingStatus, operation=PpClearDTCSettingStatus.ClearDTCSettingStatus
        OIT_CSDataServices_Data_OccurrenceCounter_Camera_Occlusion_ReadData_CSDataServices_Data_OccurrenceCounter_Camera_Occlusi824ABDF0: start-on-event=CSDataServices_Data_OccurrenceCounter_Camera_Occlusion_ReadData, operation=CSDataServices_Data_OccurrenceCounter_Camera_Occlusion.ReadData
        OIT_CSDataServices_Data_OccurrenceCounter_Current_Gear_ReadData_CSDataServices_Data_OccurrenceCounter_Current_Gear_ReadData: start-on-event=CSDataServices_Data_OccurrenceCounter_Current_Gear_ReadData, operation=CSDataServices_Data_OccurrenceCounter_Current_Gear.ReadData
        OIT_CSDataServices_Data_OccurrenceCounter_DisplayStatus_ReadData_CSDataServices_Data_OccurrenceCounter_DisplayStatus_ReadData: start-on-event=CSDataServices_Data_OccurrenceCounter_DisplayStatus_ReadData, operation=CSDataServices_Data_OccurrenceCounter_DisplayStatus.ReadData
        OIT_CSDataServices_Data_OccurrenceCounter_Door_Status_ReadData_CSDataServices_Data_OccurrenceCounter_Door_Status_ReadData: start-on-event=CSDataServices_Data_OccurrenceCounter_Door_Status_ReadData, operation=CSDataServices_Data_OccurrenceCounter_Door_Status.ReadData
        OIT_CSDataServices_Data_OccurrenceCounter_ECU_Voltage_ReadData_CSDataServices_Data_OccurrenceCounter_ECU_Voltage_ReadData: start-on-event=CSDataServices_Data_OccurrenceCounter_ECU_Voltage_ReadData, operation=CSDataServices_Data_OccurrenceCounter_ECU_Voltage.ReadData
        OIT_CSDataServices_Data_OccurrenceCounter_External_Temperature_ReadData_CSDataServices_Data_OccurrenceCounter_External_T80EFF9E8: start-on-event=CSDataServices_Data_OccurrenceCounter_External_Temperature_ReadData, operation=CSDataServices_Data_OccurrenceCounter_External_Temperature.ReadData
        OIT_CSDataServices_Data_OccurrenceCounter_Odometer_Value_ReadData_CSDataServices_Data_OccurrenceCounter_Odometer_Value_ReadData: start-on-event=CSDataServices_Data_OccurrenceCounter_Odometer_Value_ReadData, operation=CSDataServices_Data_OccurrenceCounter_Odometer_Value.ReadData
        OIT_CSDataServices_Data_OccurrenceCounter_Supplier_Internal_Code_ReadData_CSDataServices_Data_OccurrenceCounter_Supplier10DE76A6: start-on-event=CSDataServices_Data_OccurrenceCounter_Supplier_Internal_Code_ReadData, operation=CSDataServices_Data_OccurrenceCounter_Supplier_Internal_Code.ReadData
        OIT_CSDataServices_Data_OccurrenceCounter_THA_state_ReadData_CSDataServices_Data_OccurrenceCounter_THA_state_ReadData: start-on-event=CSDataServices_Data_OccurrenceCounter_THA_state_ReadData, operation=CSDataServices_Data_OccurrenceCounter_THA_state.ReadData
        OIT_CSDataServices_Data_OccurrenceCounter_TireLines_ReadData_CSDataServices_Data_OccurrenceCounter_TireLines_ReadData: start-on-event=CSDataServices_Data_OccurrenceCounter_TireLines_ReadData, operation=CSDataServices_Data_OccurrenceCounter_TireLines.ReadData
        OIT_CSDataServices_Data_OccurrenceCounter_Touch_Screen_Status_ReadData_CSDataServices_Data_OccurrenceCounter_Touch_Scree768239EB: start-on-event=CSDataServices_Data_OccurrenceCounter_Touch_Screen_Status_ReadData, operation=CSDataServices_Data_OccurrenceCounter_Touch_Screen_Status.ReadData
        OIT_CSDataServices_Data_OccurrenceCounter_Touch_Screen_X_Coordinate_ReadData_CSDataServices_Data_OccurrenceCounter_Touch59BB1B9D: start-on-event=CSDataServices_Data_OccurrenceCounter_Touch_Screen_X_Coordinate_ReadData, operation=CSDataServices_Data_OccurrenceCounter_Touch_Screen_X_Coordinate.ReadData
        OIT_CSDataServices_Data_OccurrenceCounter_Touch_Screen_Y_Coordinate_ReadData_CSDataServices_Data_OccurrenceCounter_TouchA25BFED9: start-on-event=CSDataServices_Data_OccurrenceCounter_Touch_Screen_Y_Coordinate_ReadData, operation=CSDataServices_Data_OccurrenceCounter_Touch_Screen_Y_Coordinate.ReadData
        OIT_CSDataServices_Data_OccurrenceCounter_TRSC_Stat_ReadData_CSDataServices_Data_OccurrenceCounter_TRSC_Stat_ReadData: start-on-event=CSDataServices_Data_OccurrenceCounter_TRSC_Stat_ReadData, operation=CSDataServices_Data_OccurrenceCounter_TRSC_Stat.ReadData
        OIT_CSDataServices_Data_OccurrenceCounter_Vehicle_Speed_ReadData_CSDataServices_Data_OccurrenceCounter_Vehicle_Speed_ReadData: start-on-event=CSDataServices_Data_OccurrenceCounter_Vehicle_Speed_ReadData, operation=CSDataServices_Data_OccurrenceCounter_Vehicle_Speed.ReadData
        OIT_CSDataServices_Data_OccurrenceCounter_Aging_Counter_ID_ReadData_CSDataServices_Data_OccurrenceCounter_Aging_Counter_836DD2DC: start-on-event=CSDataServices_Data_OccurrenceCounter_Aging_Counter_ID_ReadData, operation=CSDataServices_Data_OccurrenceCounter_Aging_Counter_ID.ReadData
        OIT_CSDataServices_Data_OccurrenceCounter_Frequency_Counter_ID_ReadData_CSDataServices_Data_OccurrenceCounter_Frequency_8AA32A91: start-on-event=CSDataServices_Data_OccurrenceCounter_Frequency_Counter_ID_ReadData, operation=CSDataServices_Data_OccurrenceCounter_Frequency_Counter_ID.ReadData
        OIT_CSDataServices_Data_OccurrenceCounter_Radio_Display_Status_ReadData_CSDataServices_Data_OccurrenceCounter_Radio_DispC23FCC69: start-on-event=CSDataServices_Data_OccurrenceCounter_Radio_Display_Status_ReadData, operation=CSDataServices_Data_OccurrenceCounter_Radio_Display_Status.ReadData
        OIT_CSDataServices_Data_OccurrenceCounter_TRSKM_and_USS_status_ReadData_CSDataServices_Data_OccurrenceCounter_TRSKM_and_92E0C426: start-on-event=CSDataServices_Data_OccurrenceCounter_TRSKM_and_USS_status_ReadData, operation=CSDataServices_Data_OccurrenceCounter_TRSKM_and_USS_status.ReadData
        OIT_CSDataServices_Data_OccurrenceCounter_Steering_Wheel_Angle_ReadData_CSDataServices_Data_OccurrenceCounter_Steering_W3AE030A7: start-on-event=CSDataServices_Data_OccurrenceCounter_Steering_Wheel_Angle_ReadData, operation=CSDataServices_Data_OccurrenceCounter_Steering_Wheel_Angle.ReadData
        OIT_CSDataServices_Data_OccurrenceCounter_Calibration_Not_Started_ReadData_CSDataServices_Data_OccurrenceCounter_Calibra7D502084: start-on-event=CSDataServices_Data_OccurrenceCounter_Calibration_Not_Started_ReadData, operation=CSDataServices_Data_OccurrenceCounter_Calibration_Not_Started.ReadData
        OIT_CSDataServices_Data_OccurrenceCounter_Calibration_Pending_ReadData_CSDataServices_Data_OccurrenceCounter_CalibrationCD73D052: start-on-event=CSDataServices_Data_OccurrenceCounter_Calibration_Pending_ReadData, operation=CSDataServices_Data_OccurrenceCounter_Calibration_Pending.ReadData
        OIT_CSDataServices_Data_OccurrenceCounter_Calibration_Aborted_Failed_ReadData_CSDataServices_Data_OccurrenceCounter_Cali0145BA5D: start-on-event=CSDataServices_Data_OccurrenceCounter_Calibration_Aborted_Failed_ReadData, operation=CSDataServices_Data_OccurrenceCounter_Calibration_Aborted_Failed.ReadData
        OIT_CSDataServices_Data_OccurrenceCounter_LiftgateAjar_ReadData_CSDataServices_Data_OccurrenceCounter_LiftgateAjar_ReadData: start-on-event=CSDataServices_Data_OccurrenceCounter_LiftgateAjar_ReadData, operation=CSDataServices_Data_OccurrenceCounter_LiftgateAjar.ReadData
        OIT_CSDataServices_Data_OccurrenceCounter_Calibrated_Successfully_ReadData_CSDataServices_Data_OccurrenceCounter_Calibra0DFFCB72: start-on-event=CSDataServices_Data_OccurrenceCounter_Calibrated_Successfully_ReadData, operation=CSDataServices_Data_OccurrenceCounter_Calibrated_Successfully.ReadData
        OIT_CSDataServices_Data_OccurrenceCounter_New_Bit_Field_ReadData_CSDataServices_Data_OccurrenceCounter_New_Bit_Field_ReadData: start-on-event=CSDataServices_Data_OccurrenceCounter_New_Bit_Field_ReadData, operation=CSDataServices_Data_OccurrenceCounter_New_Bit_Field.ReadData
        OIT_CSDataServices_Data_OccurrenceCounter_Calibration_Running_ReadData_CSDataServices_Data_OccurrenceCounter_CalibrationC16779BD: start-on-event=CSDataServices_Data_OccurrenceCounter_Calibration_Running_ReadData, operation=CSDataServices_Data_OccurrenceCounter_Calibration_Running.ReadData
        OIT_CSDataServices_Data_OccurrenceCounter_Reserved_1_ReadData_CSDataServices_Data_OccurrenceCounter_Reserved_1_ReadData: start-on-event=CSDataServices_Data_OccurrenceCounter_Reserved_1_ReadData, operation=CSDataServices_Data_OccurrenceCounter_Reserved_1.ReadData
        OIT_CSDataServices_Data_OccurrenceCounter_Reserved_ReadData_CSDataServices_Data_OccurrenceCounter_Reserved_ReadData: start-on-event=CSDataServices_Data_OccurrenceCounter_Reserved_ReadData, operation=CSDataServices_Data_OccurrenceCounter_Reserved.ReadData
        OIT_CSDataServices_Data_OccurrenceCounter_Cycles_to_Switch_off_the_Warning_Indication_ID_ReadData_CSDataServices_Data_OcAAD1BA9D: start-on-event=CSDataServices_Data_OccurrenceCounter_Cycles_to_Switch_off_the_Warning_Indication_ID_ReadData, operation=CSDataServices_Data_OccurrenceCounter_Cycles_to_Switch_off_the_Warning_Indication_ID.ReadData
        OIT_CSDataServices_Data_OccurrenceCounter_Reserved_2_ReadData_CSDataServices_Data_OccurrenceCounter_Reserved_2_ReadData: start-on-event=CSDataServices_Data_OccurrenceCounter_Reserved_2_ReadData, operation=CSDataServices_Data_OccurrenceCounter_Reserved_2.ReadData
        OIT_CSDataServices_Data_DID_0x1921_CombinedSignal_ReadData_CSDataServices_Data_DID_0x1921_CombinedSignal_ReadData: start-on-event=CSDataServices_Data_DID_0x1921_CombinedSignal_ReadData, operation=CSDataServices_Data_DID_0x1921_CombinedSignal.ReadData
      per-instance-parameters:
        parameter data prototype DTC_APARequestSts_PAMRequestSts_DefaultValue: sw-calibration-access=READ-WRITE, type=uint8, init-value=0
      port-api-options:
        enable-take-address=false, error-handling=NO-TRANSFORMER-ERROR-HANDLING, indirect-api=false, port=RoEMessageSRI
        enable-take-address=false, error-handling=NO-TRANSFORMER-ERROR-HANDLING, indirect-api=false, port=CSDataServices_Data_DID_0x1002_Vehicle_Speed_24
        enable-take-address=false, error-handling=NO-TRANSFORMER-ERROR-HANDLING, indirect-api=false, port=CSDataServices_Data_DID_0x1004_Battery_Voltage_24
        enable-take-address=false, error-handling=NO-TRANSFORMER-ERROR-HANDLING, indirect-api=false, port=CSDataServices_Data_DID_0x1008_ECU_Life_Time_24
        enable-take-address=false, error-handling=NO-TRANSFORMER-ERROR-HANDLING, indirect-api=false, port=CSDataServices_Data_DID_0x1009_ECU_Time_Since_Ignition_ON
        enable-take-address=false, error-handling=NO-TRANSFORMER-ERROR-HANDLING, indirect-api=false, port=CSDataServices_Data_DID_0x2001_Odometer_24
        enable-take-address=false, error-handling=NO-TRANSFORMER-ERROR-HANDLING, indirect-api=false, port=CSDataServices_Data_DID_0x200a_Ignition_ON_Counter_24
        enable-take-address=false, error-handling=NO-TRANSFORMER-ERROR-HANDLING, indirect-api=false, port=Dem_EnableCondition1
        enable-take-address=false, error-handling=NO-TRANSFORMER-ERROR-HANDLING, indirect-api=false, port=Dem_EnableCondition2
        enable-take-address=false, error-handling=NO-TRANSFORMER-ERROR-HANDLING, indirect-api=false, port=Dem_EnableCondition4
        enable-take-address=false, error-handling=NO-TRANSFORMER-ERROR-HANDLING, indirect-api=false, port=Dem_EnableCondition7
        enable-take-address=false, error-handling=NO-TRANSFORMER-ERROR-HANDLING, indirect-api=false, port=Dem_OperationCycle
        enable-take-address=false, error-handling=NO-TRANSFORMER-ERROR-HANDLING, indirect-api=false, port=RpEventDTC_B12852A
        enable-take-address=false, error-handling=NO-TRANSFORMER-ERROR-HANDLING, indirect-api=false, port=RpEventDTC_B128E13
        enable-take-address=false, error-handling=NO-TRANSFORMER-ERROR-HANDLING, indirect-api=false, port=RpEventDTC_B128E92
        enable-take-address=false, error-handling=NO-TRANSFORMER-ERROR-HANDLING, indirect-api=false, port=RpEventDTC_B128F13
        enable-take-address=false, error-handling=NO-TRANSFORMER-ERROR-HANDLING, indirect-api=false, port=RpEventDTC_B128F92
        enable-take-address=false, error-handling=NO-TRANSFORMER-ERROR-HANDLING, indirect-api=false, port=RpEventDTC_B129013
        enable-take-address=false, error-handling=NO-TRANSFORMER-ERROR-HANDLING, indirect-api=false, port=RpEventDTC_B129092
        enable-take-address=false, error-handling=NO-TRANSFORMER-ERROR-HANDLING, indirect-api=false, port=RpEventDTC_B129113
        enable-take-address=false, error-handling=NO-TRANSFORMER-ERROR-HANDLING, indirect-api=false, port=RpEventDTC_B129192
        enable-take-address=false, error-handling=NO-TRANSFORMER-ERROR-HANDLING, indirect-api=false, port=RpEventDTC_B129213
        enable-take-address=false, error-handling=NO-TRANSFORMER-ERROR-HANDLING, indirect-api=false, port=RpEventDTC_B129292
        enable-take-address=false, error-handling=NO-TRANSFORMER-ERROR-HANDLING, indirect-api=false, port=RpEventDTC_B129313
        enable-take-address=false, error-handling=NO-TRANSFORMER-ERROR-HANDLING, indirect-api=false, port=RpEventDTC_B129392
        enable-take-address=false, error-handling=NO-TRANSFORMER-ERROR-HANDLING, indirect-api=false, port=RpEventDTC_B129413
        enable-take-address=false, error-handling=NO-TRANSFORMER-ERROR-HANDLING, indirect-api=false, port=RpEventDTC_B129492
        enable-take-address=false, error-handling=NO-TRANSFORMER-ERROR-HANDLING, indirect-api=false, port=RpEventDTC_B129513
        enable-take-address=false, error-handling=NO-TRANSFORMER-ERROR-HANDLING, indirect-api=false, port=RpEventDTC_B129592
        enable-take-address=false, error-handling=NO-TRANSFORMER-ERROR-HANDLING, indirect-api=false, port=RpEventDTC_B129613
        enable-take-address=false, error-handling=NO-TRANSFORMER-ERROR-HANDLING, indirect-api=false, port=RpEventDTC_B129692
        enable-take-address=false, error-handling=NO-TRANSFORMER-ERROR-HANDLING, indirect-api=false, port=RpEventDTC_B129713
        enable-take-address=false, error-handling=NO-TRANSFORMER-ERROR-HANDLING, indirect-api=false, port=RpEventDTC_B129792
        enable-take-address=false, error-handling=NO-TRANSFORMER-ERROR-HANDLING, indirect-api=false, port=RpEventDTC_B129813
        enable-take-address=false, error-handling=NO-TRANSFORMER-ERROR-HANDLING, indirect-api=false, port=RpEventDTC_B129892
        enable-take-address=false, error-handling=NO-TRANSFORMER-ERROR-HANDLING, indirect-api=false, port=RpEventDTC_B129913
        enable-take-address=false, error-handling=NO-TRANSFORMER-ERROR-HANDLING, indirect-api=false, port=RpEventDTC_B129992
        enable-take-address=false, error-handling=NO-TRANSFORMER-ERROR-HANDLING, indirect-api=false, port=RpEventDTC_B12B22A
        enable-take-address=false, error-handling=NO-TRANSFORMER-ERROR-HANDLING, indirect-api=false, port=RpEventDTC_B210C16
        enable-take-address=false, error-handling=NO-TRANSFORMER-ERROR-HANDLING, indirect-api=false, port=RpEventDTC_B210C17
        enable-take-address=false, error-handling=NO-TRANSFORMER-ERROR-HANDLING, indirect-api=false, port=RpEventDTC_B212A08
        enable-take-address=false, error-handling=NO-TRANSFORMER-ERROR-HANDLING, indirect-api=false, port=RpEventDTC_B212A16
        enable-take-address=false, error-handling=NO-TRANSFORMER-ERROR-HANDLING, indirect-api=false, port=RpEventDTC_B212A17
        enable-take-address=false, error-handling=NO-TRANSFORMER-ERROR-HANDLING, indirect-api=false, port=RpEventDTC_B212B08
        enable-take-address=false, error-handling=NO-TRANSFORMER-ERROR-HANDLING, indirect-api=false, port=RpEventDTC_B212B16
        enable-take-address=false, error-handling=NO-TRANSFORMER-ERROR-HANDLING, indirect-api=false, port=RpEventDTC_B212B17
        enable-take-address=false, error-handling=NO-TRANSFORMER-ERROR-HANDLING, indirect-api=false, port=RpEventDTC_B217A1C
        enable-take-address=false, error-handling=NO-TRANSFORMER-ERROR-HANDLING, indirect-api=false, port=RpEventDTC_B217A92
        enable-take-address=false, error-handling=NO-TRANSFORMER-ERROR-HANDLING, indirect-api=false, port=RpEventDTC_B223B00
        enable-take-address=false, error-handling=NO-TRANSFORMER-ERROR-HANDLING, indirect-api=false, port=RpEventDTC_B228600
        enable-take-address=false, error-handling=NO-TRANSFORMER-ERROR-HANDLING, indirect-api=false, port=RpEventDTC_B22A900
        enable-take-address=false, error-handling=NO-TRANSFORMER-ERROR-HANDLING, indirect-api=false, port=RpEventDTC_B23C51C
        enable-take-address=false, error-handling=NO-TRANSFORMER-ERROR-HANDLING, indirect-api=false, port=RpEventDTC_B23C592
        enable-take-address=false, error-handling=NO-TRANSFORMER-ERROR-HANDLING, indirect-api=false, port=RpEventDTC_B23C61C
        enable-take-address=false, error-handling=NO-TRANSFORMER-ERROR-HANDLING, indirect-api=false, port=RpEventDTC_B23C692
        enable-take-address=false, error-handling=NO-TRANSFORMER-ERROR-HANDLING, indirect-api=false, port=RpEventDTC_B23C71C
        enable-take-address=false, error-handling=NO-TRANSFORMER-ERROR-HANDLING, indirect-api=false, port=RpEventDTC_B23C792
        enable-take-address=false, error-handling=NO-TRANSFORMER-ERROR-HANDLING, indirect-api=false, port=RpEventDTC_C221200
        enable-take-address=false, error-handling=NO-TRANSFORMER-ERROR-HANDLING, indirect-api=false, port=RpEventDTC_U010000
        enable-take-address=false, error-handling=NO-TRANSFORMER-ERROR-HANDLING, indirect-api=false, port=RpEventDTC_U012900
        enable-take-address=false, error-handling=NO-TRANSFORMER-ERROR-HANDLING, indirect-api=false, port=RpEventDTC_U013100
        enable-take-address=false, error-handling=NO-TRANSFORMER-ERROR-HANDLING, indirect-api=false, port=RpEventDTC_U014000
        enable-take-address=false, error-handling=NO-TRANSFORMER-ERROR-HANDLING, indirect-api=false, port=RpEventDTC_U015100
        enable-take-address=false, error-handling=NO-TRANSFORMER-ERROR-HANDLING, indirect-api=false, port=RpEventDTC_U018400
        enable-take-address=false, error-handling=NO-TRANSFORMER-ERROR-HANDLING, indirect-api=false, port=RpEventDTC_U026400
        enable-take-address=false, error-handling=NO-TRANSFORMER-ERROR-HANDLING, indirect-api=false, port=RpEventDTC_U026500
        enable-take-address=false, error-handling=NO-TRANSFORMER-ERROR-HANDLING, indirect-api=false, port=RpEventDTC_U026600
        enable-take-address=false, error-handling=NO-TRANSFORMER-ERROR-HANDLING, indirect-api=false, port=RpEventDTC_U026700
        enable-take-address=false, error-handling=NO-TRANSFORMER-ERROR-HANDLING, indirect-api=false, port=RpEventDTC_U040100
        enable-take-address=false, error-handling=NO-TRANSFORMER-ERROR-HANDLING, indirect-api=false, port=RpEventDTC_U041800
        enable-take-address=false, error-handling=NO-TRANSFORMER-ERROR-HANDLING, indirect-api=false, port=RpEventDTC_U042000
        enable-take-address=false, error-handling=NO-TRANSFORMER-ERROR-HANDLING, indirect-api=false, port=RpEventDTC_U042200
        enable-take-address=false, error-handling=NO-TRANSFORMER-ERROR-HANDLING, indirect-api=false, port=RpEventDTC_U045500
        enable-take-address=false, error-handling=NO-TRANSFORMER-ERROR-HANDLING, indirect-api=false, port=RpEventDTC_U048500
        enable-take-address=false, error-handling=NO-TRANSFORMER-ERROR-HANDLING, indirect-api=false, port=RpEventDTC_U100B00
        enable-take-address=false, error-handling=NO-TRANSFORMER-ERROR-HANDLING, indirect-api=false, port=RpEventDTC_U104E00
        enable-take-address=false, error-handling=NO-TRANSFORMER-ERROR-HANDLING, indirect-api=false, port=RpEventDTC_U12B900
        enable-take-address=false, error-handling=NO-TRANSFORMER-ERROR-HANDLING, indirect-api=false, port=RpEventDTC_U14A000
        enable-take-address=false, error-handling=NO-TRANSFORMER-ERROR-HANDLING, indirect-api=false, port=RpECUTimeSinceIGON
        enable-take-address=false, error-handling=NO-TRANSFORMER-ERROR-HANDLING, indirect-api=false, port=RpECUTimeStamp
        enable-take-address=false, error-handling=NO-TRANSFORMER-ERROR-HANDLING, indirect-api=false, port=RpIgOnCounter
      42 x runnable:
        RE_DTCMgr_Init  # Init Runnable
        RE_DTCMgr_Main  # Periodic Runnable of Satellite
          data-receive-point-by-arguments:
            47 x access:
              REC_RoEMessageSRI_Data: accessed-variable=RoEMessageSRI.Data
              REC_RpECUTimeSinceIGON_ECUTimeStamp_IGON: accessed-variable=RpECUTimeSinceIGON.ECUTimeStamp_IGON
              REC_RpECUTimeStamp_ECUTimeStamp: accessed-variable=RpECUTimeStamp.ECUTimeStamp
              REC_RpIgOnCounter_IGCounter: accessed-variable=RpIgOnCounter.IGCounter
              REC_RpSystemStateManager_SysM_State: accessed-variable=RpSystemStateManager.SysM_State
              REC_RpProxiToSWC_SurroundViewCam_u8: accessed-variable=RpProxiToSWC.SurroundViewCam_u8
              REC_RpProxiToSWC_TyreSz_u16: accessed-variable=RpProxiToSWC.TyreSz_u16
              REC_RpSnsrFnctnlTstFlg_SensorFunctionalTestFlag: accessed-variable=PpRpSnsrFnctnlTstFlg.SensorFunctionalTestFlag
              REC_RpToSwcFD02Rx_Battery_Volt_1: accessed-variable=RpToSwcFD02Rx.Battery_Volt_1
              REC_RpToSwcSafeFD02Rx_CmdIgnSts: accessed-variable=RpToSwcSafeFD02Rx.CmdIgnSts
              REC_RpToSwcSafeFD14Rx_FD14_VehicleSpeedVSOSig: accessed-variable=RpToSwcSafeFD14Rx.FD14_VehicleSpeedVSOSig
              REC_RpToSwcFD02Rx_OperationalModeSts: accessed-variable=RpToSwcFD02Rx.OperationalModeSts
              REC_RpToSwcFD02Rx_TotalOdometer: accessed-variable=RpToSwcFD02Rx.TotalOdometer
              REC_RpPlantMode_Status: accessed-variable=RpPlantMode.Status
              REC_R_DtcData_B_Data_DtcAddData_B: accessed-variable=R_DtcData_B.Data_DtcAddData_B
              REC_R_DtcData_B_Data_DtcStatus_B: accessed-variable=R_DtcData_B.Data_DtcStatus_B
              REC_R_DtcData_QM_Data_DtcAddData_QM: accessed-variable=R_DtcData_QM.Data_DtcAddData_QM
              REC_R_DtcData_QM_Data_DtcStatus_QM: accessed-variable=R_DtcData_QM.Data_DtcStatus_QM
              REC_RpToSwcSafeFD02Rx_GearEngaged: accessed-variable=RpToSwcSafeFD02Rx.GearEngaged
              REC_RpToSwcSafeFD02Rx_ExternalTemperature: accessed-variable=RpToSwcSafeFD02Rx.ExternalTemperature
              REC_RpToSwcSafeFD14Rx_FD14_LwsAngle: accessed-variable=RpToSwcSafeFD14Rx.FD14_LwsAngle
              REC_RpToSwcSafeFD02Rx_PsngrDoorSts: accessed-variable=RpToSwcSafeFD02Rx.PsngrDoorSts
              REC_RpToSwcSafeFD02Rx_DriverDoorSts: accessed-variable=RpToSwcSafeFD02Rx.DriverDoorSts
              REC_RpToSwcSafeFD02Rx_LHRDoorSts: accessed-variable=RpToSwcSafeFD02Rx.LHRDoorSts
              REC_RpToSwcSafeFD02Rx_RHRDoorSts: accessed-variable=RpToSwcSafeFD02Rx.RHRDoorSts
              REC_RpToSwcSafeFD02Rx_RHatchSts: accessed-variable=RpToSwcSafeFD02Rx.RHatchSts
              REC_RpToSwcSafeFD02Rx_ShiftLeverPosition: accessed-variable=RpToSwcSafeFD02Rx.ShiftLeverPosition
              REC_RpToSwcSafeFD02Rx_TGW_CAMERA_DISP_STAT: accessed-variable=RpToSwcSafeFD02Rx.TGW_CAMERA_DISP_STAT
              REC_RpToSwcFD02Rx_TRSC_EnableBtn_Sts: accessed-variable=RpToSwcFD02Rx.TRSC_EnableBtn_Sts
              REC_RpCalDataProviderNvmData_CalData_mcu1_0: accessed-variable=RpCalDataProviderNvmData.CalData_mcu1_0
              REC_RpToSwcSafeFD02Rx_Fwrd_Cam_Guidelines: accessed-variable=RpToSwcSafeFD02Rx.Fwrd_Cam_Guidelines
              REC_RpToSwcSafeFD02Tx_DisplayView2: accessed-variable=RpToSwcSafeFD02Tx.DisplayView2
              REC_RpToSwcFD02Tx_THA_STAT: accessed-variable=RpToSwcFD02Tx.THA_STAT
              REC_RpToSwcFD02Tx_TRSC_STAT: accessed-variable=RpToSwcFD02Tx.TRSC_STAT
              REC_RpDLDOutput_JobDLDOutput_t: accessed-variable=RpDLDOutput.JobDLDOutput_t
              REC_RpToSwcSafeFD14Rx_FD14_ESS_ENG_ST_W: accessed-variable=RpToSwcSafeFD14Rx.FD14_ESS_ENG_ST_W
              REC_RpToSwcSafeFD02Rx_CameraDisplaySts2: accessed-variable=RpToSwcSafeFD02Rx.CameraDisplaySts2
              REC_RpToSwcSafeFD02Rx_CM_TCH_STAT: accessed-variable=RpToSwcSafeFD02Rx.CM_TCH_STAT
              REC_RpToSwcSafeFD02Rx_CM_TCH_X_COORD: accessed-variable=RpToSwcSafeFD02Rx.CM_TCH_X_COORD
              REC_RpToSwcSafeFD02Rx_CM_TCH_Y_COORD: accessed-variable=RpToSwcSafeFD02Rx.CM_TCH_Y_COORD
              REC_RpErrors_B_Errors_B: accessed-variable=RpErrors_B.Errors_B
              REC_RpErrors_QM_Errors_QM: accessed-variable=RpErrors_QM.Errors_QM
              REC_RpToSwcSafeFD02Tx_ParkingManeuverActive: accessed-variable=RpToSwcSafeFD02Tx.ParkingManeuverActive
              REC_RpProxiToSWC_Fullautomaticparking: accessed-variable=RpProxiToSWC.Fullautomaticparking
              REC_RpAPSMPAOut_TbAP_APSMPAOut_t: accessed-variable=RpAPSMPAOut.TbAP_APSMPAOut_t
              REC_RpToSwcSafeFD02Rx_APARequestSts: accessed-variable=RpToSwcSafeFD02Rx.APARequestSts
              REC_PRpDtcSettingClearFlagModeGrp_requestedMode: accessed-variable=PRpDtcSettingClearFlagModeGrp.requestedMode
          data-send-points:
            access SEND_PRpDtcSettingClearFlagModeGrp_requestedMode: accessed-variable=PRpDtcSettingClearFlagModeGrp.requestedMode
            access SEND_PpDtcB12852AData_v_DtcData_u8: accessed-variable=PpDtcB12852AData.v_DtcData_u8
            access SEND_PpRpSnsrFnctnlTstFlg_SensorFunctionalTestFlag: accessed-variable=PpRpSnsrFnctnlTstFlg.SensorFunctionalTestFlag
          82 x sync call:
            SC_Dem_EnableCondition1_SetEnableCondition: operation=Dem_EnableCondition1.SetEnableCondition
            SC_Dem_EnableCondition2_SetEnableCondition: operation=Dem_EnableCondition2.SetEnableCondition
            SC_Dem_EnableCondition4_SetEnableCondition: operation=Dem_EnableCondition4.SetEnableCondition
            SC_Dem_EnableCondition5_SetEnableCondition: operation=Dem_EnableCondition5.SetEnableCondition
            SC_Dem_EnableCondition7_SetEnableCondition: operation=Dem_EnableCondition7.SetEnableCondition
            SC_Dem_OperationCycle_GetOperationCycleState: operation=Dem_OperationCycle.GetOperationCycleState
            SC_Dem_OperationCycle_SetOperationCycleState: operation=Dem_OperationCycle.SetOperationCycleState
            SC_RpEventDTC_B12B22A_SetEventStatus: operation=RpEventDTC_B12B22A.SetEventStatus
            SC_RpEventDTC_B22A900_SetEventStatus: operation=RpEventDTC_B22A900.SetEventStatus
            SC_RpEventDTC_B23C51C_SetEventStatus: operation=RpEventDTC_B23C51C.SetEventStatus
            SC_RpEventDTC_B23C61C_SetEventStatus: operation=RpEventDTC_B23C61C.SetEventStatus
            SC_RpEventDTC_B23C71C_SetEventStatus: operation=RpEventDTC_B23C71C.SetEventStatus
            SC_RpEventDTC_B23C592_SetEventStatus: operation=RpEventDTC_B23C592.SetEventStatus
            SC_RpEventDTC_B23C692_SetEventStatus: operation=RpEventDTC_B23C692.SetEventStatus
            SC_RpEventDTC_B23C792_SetEventStatus: operation=RpEventDTC_B23C792.SetEventStatus
            SC_RpEventDTC_B128E13_SetEventStatus: operation=RpEventDTC_B128E13.SetEventStatus
            SC_RpEventDTC_B128E92_SetEventStatus: operation=RpEventDTC_B128E92.SetEventStatus
            SC_RpEventDTC_B128F13_SetEventStatus: operation=RpEventDTC_B128F13.SetEventStatus
            SC_RpEventDTC_B128F92_SetEventStatus: operation=RpEventDTC_B128F92.SetEventStatus
            SC_RpEventDTC_B210C16_SetEventStatus: operation=RpEventDTC_B210C16.SetEventStatus
            SC_RpEventDTC_B210C17_SetEventStatus: operation=RpEventDTC_B210C17.SetEventStatus
            SC_RpEventDTC_B212A08_SetEventStatus: operation=RpEventDTC_B212A08.SetEventStatus
            SC_RpEventDTC_B212A16_SetEventStatus: operation=RpEventDTC_B212A16.SetEventStatus
            SC_RpEventDTC_B212A17_SetEventStatus: operation=RpEventDTC_B212A17.SetEventStatus
            SC_RpEventDTC_B212B08_SetEventStatus: operation=RpEventDTC_B212B08.SetEventStatus
            SC_RpEventDTC_B212B16_SetEventStatus: operation=RpEventDTC_B212B16.SetEventStatus
            SC_RpEventDTC_B212B17_SetEventStatus: operation=RpEventDTC_B212B17.SetEventStatus
            SC_RpEventDTC_B217A1C_SetEventStatus: operation=RpEventDTC_B217A1C.SetEventStatus
            SC_RpEventDTC_B217A92_SetEventStatus: operation=RpEventDTC_B217A92.SetEventStatus
            SC_RpEventDTC_B223B00_SetEventStatus: operation=RpEventDTC_B223B00.SetEventStatus
            SC_RpEventDTC_B12852A_SetEventStatus: operation=RpEventDTC_B12852A.SetEventStatus
            SC_RpEventDTC_B129013_SetEventStatus: operation=RpEventDTC_B129013.SetEventStatus
            SC_RpEventDTC_B129092_SetEventStatus: operation=RpEventDTC_B129092.SetEventStatus
            SC_RpEventDTC_B129113_SetEventStatus: operation=RpEventDTC_B129113.SetEventStatus
            SC_RpEventDTC_B129192_SetEventStatus: operation=RpEventDTC_B129192.SetEventStatus
            SC_RpEventDTC_B129213_SetEventStatus: operation=RpEventDTC_B129213.SetEventStatus
            SC_RpEventDTC_B129292_SetEventStatus: operation=RpEventDTC_B129292.SetEventStatus
            SC_RpEventDTC_B129313_SetEventStatus: operation=RpEventDTC_B129313.SetEventStatus
            SC_RpEventDTC_B129392_SetEventStatus: operation=RpEventDTC_B129392.SetEventStatus
            SC_RpEventDTC_B129413_SetEventStatus: operation=RpEventDTC_B129413.SetEventStatus
            SC_RpEventDTC_B129492_SetEventStatus: operation=RpEventDTC_B129492.SetEventStatus
            SC_RpEventDTC_B129513_SetEventStatus: operation=RpEventDTC_B129513.SetEventStatus
            SC_RpEventDTC_B129592_SetEventStatus: operation=RpEventDTC_B129592.SetEventStatus
            SC_RpEventDTC_B129613_SetEventStatus: operation=RpEventDTC_B129613.SetEventStatus
            SC_RpEventDTC_B129692_SetEventStatus: operation=RpEventDTC_B129692.SetEventStatus
            SC_RpEventDTC_B129713_SetEventStatus: operation=RpEventDTC_B129713.SetEventStatus
            SC_RpEventDTC_B129792_SetEventStatus: operation=RpEventDTC_B129792.SetEventStatus
            SC_RpEventDTC_B129813_SetEventStatus: operation=RpEventDTC_B129813.SetEventStatus
            SC_RpEventDTC_B129892_SetEventStatus: operation=RpEventDTC_B129892.SetEventStatus
            SC_RpEventDTC_B129913_SetEventStatus: operation=RpEventDTC_B129913.SetEventStatus
            SC_RpEventDTC_B129992_SetEventStatus: operation=RpEventDTC_B129992.SetEventStatus
            SC_RpEventDTC_B228600_SetEventStatus: operation=RpEventDTC_B228600.SetEventStatus
            SC_RpEventDTC_C221200_SetEventStatus: operation=RpEventDTC_C221200.SetEventStatus
            SC_RpEventDTC_U12B900_SetEventStatus: operation=RpEventDTC_U12B900.SetEventStatus
            SC_RpEventDTC_U14A000_SetEventStatus: operation=RpEventDTC_U14A000.SetEventStatus
            SC_RpEventDTC_U100B00_SetEventStatus: operation=RpEventDTC_U100B00.SetEventStatus
            SC_RpEventDTC_U104E00_SetEventStatus: operation=RpEventDTC_U104E00.SetEventStatus
            SC_RpEventDTC_U010000_SetEventStatus: operation=RpEventDTC_U010000.SetEventStatus
            SC_RpEventDTC_U012900_SetEventStatus: operation=RpEventDTC_U012900.SetEventStatus
            SC_RpEventDTC_U013100_SetEventStatus: operation=RpEventDTC_U013100.SetEventStatus
            SC_RpEventDTC_U014000_SetEventStatus: operation=RpEventDTC_U014000.SetEventStatus
            SC_RpEventDTC_U015100_SetEventStatus: operation=RpEventDTC_U015100.SetEventStatus
            SC_RpEventDTC_U018400_SetEventStatus: operation=RpEventDTC_U018400.SetEventStatus
            SC_RpEventDTC_U026400_SetEventStatus: operation=RpEventDTC_U026400.SetEventStatus
            SC_RpEventDTC_U026500_SetEventStatus: operation=RpEventDTC_U026500.SetEventStatus
            SC_RpEventDTC_U026600_SetEventStatus: operation=RpEventDTC_U026600.SetEventStatus
            SC_RpEventDTC_U026700_SetEventStatus: operation=RpEventDTC_U026700.SetEventStatus
            SC_RpEventDTC_U040100_SetEventStatus: operation=RpEventDTC_U040100.SetEventStatus
            SC_RpEventDTC_U041800_SetEventStatus: operation=RpEventDTC_U041800.SetEventStatus
            SC_RpEventDTC_U042000_SetEventStatus: operation=RpEventDTC_U042000.SetEventStatus
            SC_RpEventDTC_U042200_SetEventStatus: operation=RpEventDTC_U042200.SetEventStatus
            SC_RpEventDTC_U045500_SetEventStatus: operation=RpEventDTC_U045500.SetEventStatus
            SC_RpEventDTC_U048500_SetEventStatus: operation=RpEventDTC_U048500.SetEventStatus
            SC_RpReadVoltInfo_GetVoltageInfo: operation=RpReadVoltInfo.GetVoltageInfo
            SC_RpEventDTC_U104E00_GetEventStatus: operation=RpEventDTC_U104E00.GetEventStatus
            SC_Dem_EnableCondition1_4_8_SetEnableCondition: operation=Dem_EnableCondition1_4_8.SetEnableCondition
            SC_Dem_EnableCondition1_8_SetEnableCondition: operation=Dem_EnableCondition1_8.SetEnableCondition
            SC_Dem_EnableCondition9_SetEnableCondition: operation=Dem_EnableCondition9.SetEnableCondition
            SC_RpEventDTC_P060200_SetEventStatus: operation=RpEventDTC_P060200.SetEventStatus
            SC_NvMService_AC3_SRBS_DTC_APARequestSts_PAMRequestSts_SetRamBlockStatus: operation=NvMService_AC3_SRBS_DTC_APARequestSts_PAMRequestSts.SetRamBlockStatus
            SC_RpIpcTxData_IPC_Write_v: operation=RpIpcTxData.IPC_Write_v
            SC_Dem_EnableCondition10_SetEnableCondition: operation=Dem_EnableCondition10.SetEnableCondition
        CSDataServices_Data_DID_0x1008_ECU_Life_Time_24_ReadData
        CSDataServices_Data_DID_0x1002_Vehicle_Speed_24_ReadData
        CSDataServices_Data_DID_0x1009_ECU_Time_Since_Ignition_ON_ReadData
        CSDataServices_Data_DID_0x200a_Ignition_ON_Counter_24_ReadData
        CSDataServices_Data_DID_0x2001_Odometer_24_ReadData
        CSDataServices_Data_DID_0x1004_Battery_Voltage_24_ReadData
        RE_DTCMgr_EtROEMessage
          data-receive-point-by-arguments:
            access REC_RoEMessageSRI_Data: accessed-variable=RoEMessageSRI.Data
          data-send-points:
            access SEND_PpToComFD02Tx_N_PDU: accessed-variable=PpToComFD02Tx.N_PDU
        RE_ClearDTCSettingStatus
        CSDataServices_Data_OccurrenceCounter_Camera_Occlusion_ReadData
        CSDataServices_Data_OccurrenceCounter_Current_Gear_ReadData
        CSDataServices_Data_OccurrenceCounter_DisplayStatus_ReadData
        CSDataServices_Data_OccurrenceCounter_Door_Status_ReadData
        CSDataServices_Data_OccurrenceCounter_ECU_Voltage_ReadData
        CSDataServices_Data_OccurrenceCounter_External_Temperature_ReadData
        CSDataServices_Data_OccurrenceCounter_Odometer_Value_ReadData
        CSDataServices_Data_OccurrenceCounter_Radio_Display_Status_ReadData
        CSDataServices_Data_OccurrenceCounter_Supplier_Internal_Code_ReadData
        CSDataServices_Data_OccurrenceCounter_THA_state_ReadData
        CSDataServices_Data_OccurrenceCounter_TireLines_ReadData
        CSDataServices_Data_OccurrenceCounter_Touch_Screen_Status_ReadData
        CSDataServices_Data_OccurrenceCounter_Touch_Screen_X_Coordinate_ReadData
        CSDataServices_Data_OccurrenceCounter_Touch_Screen_Y_Coordinate_ReadData
        CSDataServices_Data_OccurrenceCounter_TRSC_Stat_ReadData
        CSDataServices_Data_OccurrenceCounter_Vehicle_Speed_ReadData
        CSDataServices_Data_OccurrenceCounter_Aging_Counter_ID_ReadData
        CSDataServices_Data_OccurrenceCounter_Frequency_Counter_ID_ReadData
        CSDataServices_Data_OccurrenceCounter_TRSKM_and_USS_status_ReadData
          data-receive-point-by-arguments:
            access REC_RpProxiToSWC_Pamtuningset: accessed-variable=RpProxiToSWC.Pamtuningset
        CSDataServices_Data_OccurrenceCounter_Steering_Wheel_Angle_ReadData
        CSDataServices_Data_OccurrenceCounter_Calibration_Not_Started_ReadData
        CSDataServices_Data_OccurrenceCounter_Calibration_Pending_ReadData
        CSDataServices_Data_OccurrenceCounter_Calibration_Aborted_Failed_ReadData
        CSDataServices_Data_OccurrenceCounter_LiftgateAjar_ReadData
        CSDataServices_Data_OccurrenceCounter_Calibrated_Successfully_ReadData
        CSDataServices_Data_OccurrenceCounter_New_Bit_Field_ReadData
        CSDataServices_Data_OccurrenceCounter_Calibration_Running_ReadData
        CSDataServices_Data_OccurrenceCounter_Reserved_1_ReadData
        CSDataServices_Data_OccurrenceCounter_Reserved_ReadData
        CSDataServices_Data_OccurrenceCounter_Cycles_to_Switch_off_the_Warning_Indication_ID_ReadData
        CSDataServices_Data_OccurrenceCounter_Reserved_2_ReadData
        CSDataServices_Data_DID_0x1921_CombinedSignal_ReadData
      swc service dependency DTC_APARequestSts_PAMRequestSts: category=SERVICE, assigned-ports=role-based-port-assignment={port-prototype=NvMService_AC3_SRBS_DTC_APARequestSts_PAMRequestSts, role=NvMService_AC3_SRBS}
        assigned-datas:
          role=ramBlock, used-data-element=DTC_APARequestSts_PAMRequestSts_MirrorBlock
          role=defaultValue, used-parameter-element=DTC_APARequestSts_PAMRequestSts_DefaultValue
        service-needs:
          nv block needs DTC_APARequestSts_PAMRequestSts: n-data-sets=1, ram-block-status-control=API, reliability=NO-PROTECTION, restore-at-start=true, store-at-shutdown=true
  swc implementation SWC_DTCMgr_Implementation: programming-language=C, vendor-id=0, behavior=SWC_DTCMgr_InternalBehavior
    code-descriptors:
      code Default: artifact-descriptors=autosar-engineering-object=category=SWSRC
